[part 3 of 3: package /MICROSAR/Dcm_swc/ComponentTypes]
AUTOSAR XML (schema 00049)
package /MICROSAR/Dcm_swc/ComponentTypes
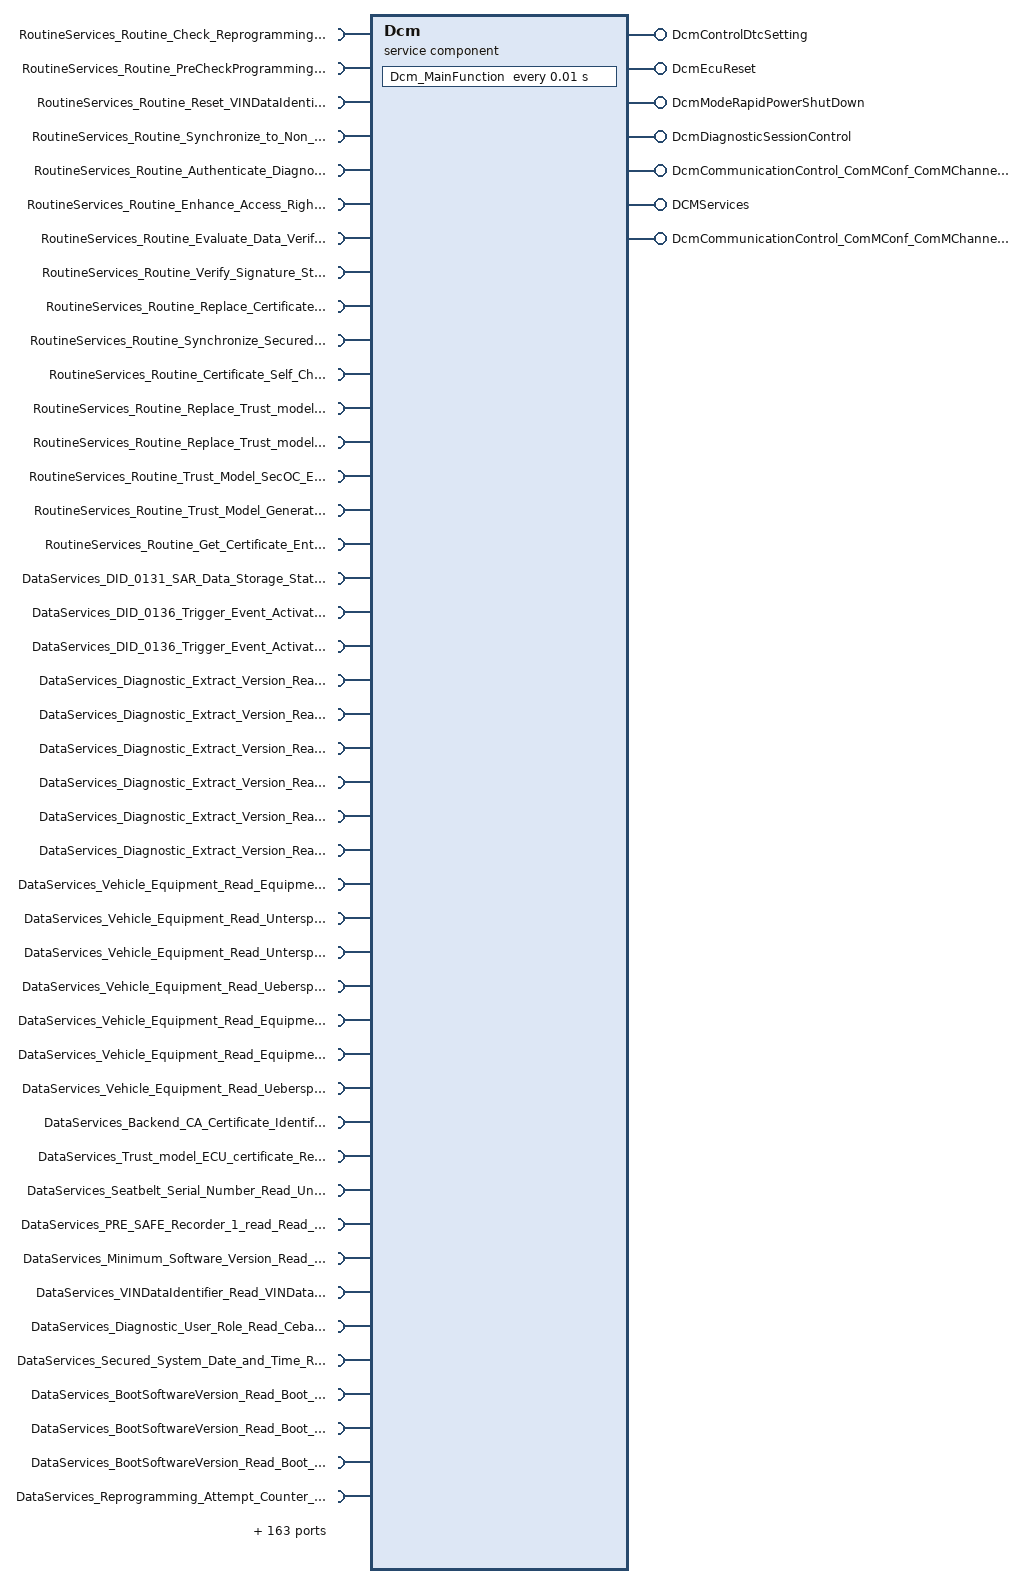
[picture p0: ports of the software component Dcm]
  service sw component type Dcm: category=SERVICE_COMPONENT
    6 x provide port:
      DcmControlDtcSetting: provided-interface=DcmControlDtcSetting
      DcmEcuReset: mode-switch-sender-com-spec{mode-group=DcmEcuReset, mode-switched-ack=timeout=0}, provided-interface=DcmEcuReset
      DcmModeRapidPowerShutDown: mode-switch-sender-com-spec{mode-group=DcmModeRapidPowerShutDown, mode-switched-ack=timeout=0}, provided-interface=DcmModeRapidPowerShutDown
      DcmDiagnosticSessionControl: provided-interface=DcmDiagnosticSessionControl
      DcmCommunicationControl_ComMConf_ComMChannel_RBTM_FL_BODY3_8uqv9blm85ehm0msat385m76v_03d5f5f6: provided-interface=DcmCommunicationControl_ComMConf_ComMChannel_RBTM_FL_BODY3_8uqv9blm85ehm0msat385m76v_03d5f5f6
      DCMServices: provided-interface=DCMServices
    138 x require port:
      RoutineServices_Routine_Check_Reprogramming_Preconditions_Start: required-interface=RoutineServices_Routine_Check_Reprogramming_Preconditions_Start
      RoutineServices_Routine_PreCheckProgrammingDependencies_Start: required-interface=RoutineServices_Routine_PreCheckProgrammingDependencies_Start
      RoutineServices_Routine_Reset_VINDataIdentifier_Start: required-interface=RoutineServices_Routine_Reset_VINDataIdentifier_Start
      RoutineServices_Routine_Synchronize_to_Non_volatile_Memory_Start: required-interface=RoutineServices_Routine_Synchronize_to_Non_volatile_Memory_Start
      RoutineServices_Routine_Authenticate_Diagnostic_User_or_Tester_Start: required-interface=RoutineServices_Routine_Authenticate_Diagnostic_User_or_Tester_Start
      RoutineServices_Routine_Enhance_Access_Rights_Start: required-interface=RoutineServices_Routine_Enhance_Access_Rights_Start
      RoutineServices_Routine_Evaluate_Data_Verification_Certificate_Start: required-interface=RoutineServices_Routine_Evaluate_Data_Verification_Certificate_Start
      RoutineServices_Routine_Verify_Signature_Start: required-interface=RoutineServices_Routine_Verify_Signature_Start
      RoutineServices_Routine_Replace_Certificates_Start: required-interface=RoutineServices_Routine_Replace_Certificates_Start
      RoutineServices_Routine_Synchronize_Secured_System_Date_and_Time_Start: required-interface=RoutineServices_Routine_Synchronize_Secured_System_Date_and_Time_Start
      RoutineServices_Routine_Certificate_Self_Check_Start: required-interface=RoutineServices_Routine_Certificate_Self_Check_Start
      RoutineServices_Routine_Replace_Trust_model_Certificates_Start: required-interface=RoutineServices_Routine_Replace_Trust_model_Certificates_Start
      RoutineServices_Routine_Replace_Trust_model_Root_Certificate_Start: required-interface=RoutineServices_Routine_Replace_Trust_model_Root_Certificate_Start
      RoutineServices_Routine_Trust_Model_SecOC_ECU_Shared_Secret_Distribution_Start: required-interface=RoutineServices_Routine_Trust_Model_SecOC_ECU_Shared_Secret_Distribution_Start
      RoutineServices_Routine_Trust_Model_Generate_Key_Pair_Start: required-interface=RoutineServices_Routine_Trust_Model_Generate_Key_Pair_Start
      RoutineServices_Routine_Get_Certificate_Entry_Start: required-interface=RoutineServices_Routine_Get_Certificate_Entry_Start
      DataServices_DID_0131_SAR_Data_Storage_Status: required-interface=DataServices_DID_0131_SAR_Data_Storage_Status
      DataServices_DID_0136_Trigger_Event_Activation_Status_Byte_2: required-interface=DataServices_DID_0136_Trigger_Event_Activation_Status_Byte_2
      DataServices_DID_0136_Trigger_Event_Activation_Status_Byte_1: required-interface=DataServices_DID_0136_Trigger_Event_Activation_Status_Byte_1
      DataServices_Diagnostic_Extract_Version_Read_Diagnostic_Extract_Minor_Version: required-interface=DataServices_Diagnostic_Extract_Version_Read_Diagnostic_Extract_Minor_Version
      DataServices_Diagnostic_Extract_Version_Read_CANdela_Version: required-interface=DataServices_Diagnostic_Extract_Version_Read_CANdela_Version
      DataServices_Diagnostic_Extract_Version_Read_Diagnostic_Extract_Major_Version: required-interface=DataServices_Diagnostic_Extract_Version_Read_Diagnostic_Extract_Major_Version
      DataServices_Diagnostic_Extract_Version_Read_DDM_Version: required-interface=DataServices_Diagnostic_Extract_Version_Read_DDM_Version
      DataServices_Diagnostic_Extract_Version_Read_Exported_Diagnostic_Variant: required-interface=DataServices_Diagnostic_Extract_Version_Read_Exported_Diagnostic_Variant
      DataServices_Diagnostic_Extract_Version_Read_Diagnostic_Extract_Patch_Version: required-interface=DataServices_Diagnostic_Extract_Version_Read_Diagnostic_Extract_Patch_Version
      DataServices_Vehicle_Equipment_Read_Equipment_1: required-interface=DataServices_Vehicle_Equipment_Read_Equipment_1
      DataServices_Vehicle_Equipment_Read_Unterspannungsbereichsschwelle: required-interface=DataServices_Vehicle_Equipment_Read_Unterspannungsbereichsschwelle
      DataServices_Vehicle_Equipment_Read_Unterspannungsabbruchschwelle: required-interface=DataServices_Vehicle_Equipment_Read_Unterspannungsabbruchschwelle
      DataServices_Vehicle_Equipment_Read_Ueberspannungsbereichsschwelle: required-interface=DataServices_Vehicle_Equipment_Read_Ueberspannungsbereichsschwelle
      DataServices_Vehicle_Equipment_Read_Equipment_3: required-interface=DataServices_Vehicle_Equipment_Read_Equipment_3
      DataServices_Vehicle_Equipment_Read_Equipment_2: required-interface=DataServices_Vehicle_Equipment_Read_Equipment_2
      DataServices_Vehicle_Equipment_Read_Ueberspannungsabbruchschwelle: required-interface=DataServices_Vehicle_Equipment_Read_Ueberspannungsabbruchschwelle
      DataServices_Backend_CA_Certificate_Identification_Read_Backend_CA_SubjectKeyIdentifier: required-interface=DataServices_Backend_CA_Certificate_Identification_Read_Backend_CA_SubjectKeyIdentifier
      DataServices_Trust_model_ECU_certificate_Read_Trust_model_ECU_Certificate: required-interface=DataServices_Trust_model_ECU_certificate_Read_Trust_model_ECU_Certificate
      DataServices_Seatbelt_Serial_Number_Read_Unique_Seatbelt_Serialnumber: required-interface=DataServices_Seatbelt_Serial_Number_Read_Unique_Seatbelt_Serialnumber
      DataServices_PRE_SAFE_Recorder_1_read_Read_CombinedDataElement: required-interface=DataServices_PRE_SAFE_Recorder_1_read_Read_CombinedDataElement
      DataServices_Minimum_Software_Version_Read_Minimum_Software_Version: required-interface=DataServices_Minimum_Software_Version_Read_Minimum_Software_Version
      DataServices_VINDataIdentifier_Read_VINDataIdentifier: required-interface=DataServices_VINDataIdentifier_Read_VINDataIdentifier
      DataServices_Diagnostic_User_Role_Read_Cebas_UserRole: required-interface=DataServices_Diagnostic_User_Role_Read_Cebas_UserRole
      DataServices_Secured_System_Date_and_Time_Read_GeneralizedTime: required-interface=DataServices_Secured_System_Date_and_Time_Read_GeneralizedTime
      DataServices_BootSoftwareVersion_Read_Boot_SW_year: required-interface=DataServices_BootSoftwareVersion_Read_Boot_SW_year
      DataServices_BootSoftwareVersion_Read_Boot_SW_patch_level: required-interface=DataServices_BootSoftwareVersion_Read_Boot_SW_patch_level
      DataServices_BootSoftwareVersion_Read_Boot_SW_week: required-interface=DataServices_BootSoftwareVersion_Read_Boot_SW_week
      DataServices_Reprogramming_Attempt_Counter_Read_Reprogramming_Attempts: required-interface=DataServices_Reprogramming_Attempt_Counter_Read_Reprogramming_Attempts
      DataServices_Standard_Application_SW_Package_Information_Read_Standard_Application_SW_Package_Major_Version: required-interface=DataServices_Standard_Application_SW_Package_Information_Read_Standard_Application_SW_Package_Major_Version
      DataServices_Standard_Application_SW_Package_Information_Read_Standard_Application_SW_Package_Patch_Level: required-interface=DataServices_Standard_Application_SW_Package_Information_Read_Standard_Application_SW_Package_Patch_Level
      DataServices_Standard_Application_SW_Package_Information_Read_Standard_Application_SW_Package_Minor_Version: required-interface=DataServices_Standard_Application_SW_Package_Information_Read_Standard_Application_SW_Package_Minor_Version
      DataServices_Standard_Application_SW_Package_Information_Read_Supplier_Identification: required-interface=DataServices_Standard_Application_SW_Package_Information_Read_Supplier_Identification
      DataServices_Standard_Application_SW_Package_Information_Read_Standard_Application_SW_Package_Build_Version: required-interface=DataServices_Standard_Application_SW_Package_Information_Read_Standard_Application_SW_Package_Build_Version
      DataServices_Dump_of_Vedoc_Relevant_Information_Read_PatchedObject: required-interface=DataServices_Dump_of_Vedoc_Relevant_Information_Read_PatchedObject
      DataServices_ECU_Name_Read_Diagnostic_ECU_Name: required-interface=DataServices_ECU_Name_Read_Diagnostic_ECU_Name
      DataServices_Security_Event_Log_Read_Security_Event_Log: required-interface=DataServices_Security_Event_Log_Read_Security_Event_Log
      DataServices_Adjust_ISO_15765_2_Block_Size_and_STmin_Parameter_Read_STmin_Value_as_defined_in_ISO_15765_2: required-interface=DataServices_Adjust_ISO_15765_2_Block_Size_and_STmin_Parameter_Read_STmin_Value_as_defined_in_ISO_15765_2
      DataServices_Adjust_ISO_15765_2_Block_Size_and_STmin_Parameter_Read_Block_Size_Value_as_defined_in_ISO_15765_2: required-interface=DataServices_Adjust_ISO_15765_2_Block_Size_and_STmin_Parameter_Read_Block_Size_Value_as_defined_in_ISO_15765_2
      DataServices_SSA_Version_Information_Read_SSA_Patch_Level: required-interface=DataServices_SSA_Version_Information_Read_SSA_Patch_Level
      DataServices_SSA_Version_Information_Read_SSA_Major_Version: required-interface=DataServices_SSA_Version_Information_Read_SSA_Major_Version
      DataServices_SSA_Version_Information_Read_SSA_Minor_Version: required-interface=DataServices_SSA_Version_Information_Read_SSA_Minor_Version
      DataServices_SoftwareSupplier_Read_Software_Logical_Block_Supplier_Identification: required-interface=DataServices_SoftwareSupplier_Read_Software_Logical_Block_Supplier_Identification
      DataServices_DDS_Package_Release_Read_DDS_Package_Release_of_Boot_Software_Month_Boot: required-interface=DataServices_DDS_Package_Release_Read_DDS_Package_Release_of_Boot_Software_Month_Boot
      DataServices_DDS_Package_Release_Read_DDS_Package_Release_of_Application_Software_Year_Appl: required-interface=DataServices_DDS_Package_Release_Read_DDS_Package_Release_of_Application_Software_Year_Appl
      DataServices_DDS_Package_Release_Read_DDS_Package_Release_of_Application_Software_Month_Appl: required-interface=DataServices_DDS_Package_Release_Read_DDS_Package_Release_of_Application_Software_Month_Appl
      DataServices_DDS_Package_Release_Read_DDS_Package_Release_of_Boot_Software_Year_Boot: required-interface=DataServices_DDS_Package_Release_Read_DDS_Package_Release_of_Boot_Software_Year_Boot
      DataServices_Security_Event_Log_Current_Counter_Values_Read_Security_Event_Log_Current_Counter_Values: required-interface=DataServices_Security_Event_Log_Current_Counter_Values_Read_Security_Event_Log_Current_Counter_Values
      DataServices_Supported_configuration_mechanisms_Read_Config_mechanisms: required-interface=DataServices_Supported_configuration_mechanisms_Read_Config_mechanisms
      DataServices_CAN_input_Read_Neues_Bitfeld_6: required-interface=DataServices_CAN_input_Read_Neues_Bitfeld_6
      DataServices_CAN_input_Read_Neues_Bitfeld_5: required-interface=DataServices_CAN_input_Read_Neues_Bitfeld_5
      DataServices_CAN_input_Read_Neues_Bitfeld_4: required-interface=DataServices_CAN_input_Read_Neues_Bitfeld_4
      DataServices_CAN_input_Read_Neues_Bitfeld_3: required-interface=DataServices_CAN_input_Read_Neues_Bitfeld_3
      DataServices_CAN_input_Read_Supply_battery_voltage: required-interface=DataServices_CAN_input_Read_Supply_battery_voltage
      DataServices_CAN_input_Read_Neues_Bitfeld_2: required-interface=DataServices_CAN_input_Read_Neues_Bitfeld_2
      DataServices_CAN_input_Read_Neues_Bitfeld_1: required-interface=DataServices_CAN_input_Read_Neues_Bitfeld_1
      DataServices_SecOC_Vehicle_Shared_Secret_Hash_Read_SecOC_Vehicle_Shared_Secret_Hash: required-interface=DataServices_SecOC_Vehicle_Shared_Secret_Hash_Read_SecOC_Vehicle_Shared_Secret_Hash
      DataServices_Trust_model_ECU_CSR_Read_Trust_model_ECU_CSR: required-interface=DataServices_Trust_model_ECU_CSR_Read_Trust_model_ECU_CSR
      DataServices_Root_CA_Certificate_Read_Root_CA_Certificate: required-interface=DataServices_Root_CA_Certificate_Read_Root_CA_Certificate
      DataServices_ECUSerialNumberDataIdentifier_Read_ECU_Serial_Number: required-interface=DataServices_ECUSerialNumberDataIdentifier_Read_ECU_Serial_Number
      DataServices_VIN_Status_Read_VIN_Lock_Status: required-interface=DataServices_VIN_Status_Read_VIN_Lock_Status
      DataServices_VIN_Status_Read_VIN_Status: required-interface=DataServices_VIN_Status_Read_VIN_Status
      DataServices_Status_SSA_Pre_Compile_Switches_Read_Precompile_switch: required-interface=DataServices_Status_SSA_Pre_Compile_Switches_Read_Precompile_switch
      DataServices_PRE_SAFE_Recorder_2_read_Read_CombinedDataElement: required-interface=DataServices_PRE_SAFE_Recorder_2_read_Read_CombinedDataElement
      DataServices_BSR_Counter_read_Read_BSR_Counter: required-interface=DataServices_BSR_Counter_read_Read_BSR_Counter
      DataServices_Vehicle_Odometer_in_Low_Resolution_Read_Vehicle_Odometer_in_Low_Resolution: required-interface=DataServices_Vehicle_Odometer_in_Low_Resolution_Read_Vehicle_Odometer_in_Low_Resolution
      DataServices_HardwareSupplier_Read_Hardware_Supplier_Identification: required-interface=DataServices_HardwareSupplier_Read_Hardware_Supplier_Identification
      DataServices_MercedesCarGroupSoftware_Read_Software_Logical_Block_Numbers: required-interface=DataServices_MercedesCarGroupSoftware_Read_Software_Logical_Block_Numbers
      DataServices_SecOC_PDU_Data_IDs_and_Key_CMACs_Read_Secured_PDU_Data_IDs_and_Key_CMACs: required-interface=DataServices_SecOC_PDU_Data_IDs_and_Key_CMACs_Read_Secured_PDU_Data_IDs_and_Key_CMACs
      DataServices_Current_Operating_Time_Read_Current_Operating_Time: required-interface=DataServices_Current_Operating_Time_Read_Current_Operating_Time
      DataServices_Current_Operating_Time_Read_Operating_Time_Status: required-interface=DataServices_Current_Operating_Time_Read_Operating_Time_Status
      DataServices_Trust_model_Root_CA_certificate_Read_Trust_model_Root_CA_certificate: required-interface=DataServices_Trust_model_Root_CA_certificate_Read_Trust_model_Root_CA_certificate
      DataServices_RandomNumber_Read_Generated_Random_Number_Result: required-interface=DataServices_RandomNumber_Read_Generated_Random_Number_Result
      DataServices_RandomNumber_Read_Generated_Random_Number: required-interface=DataServices_RandomNumber_Read_Generated_Random_Number
      DataServices_MercedesCarGroupHardware_Read_Hardware_Part_Number: required-interface=DataServices_MercedesCarGroupHardware_Read_Hardware_Part_Number
      DataServices_Internal_ECU_information_Read_ECU_Temperature: required-interface=DataServices_Internal_ECU_information_Read_ECU_Temperature
      DataServices_Internal_ECU_information_Read_MOTOR_Current: required-interface=DataServices_Internal_ECU_information_Read_MOTOR_Current
      DataServices_Internal_ECU_information_Read_Autosar_System_State_EcuM_State: required-interface=DataServices_Internal_ECU_information_Read_Autosar_System_State_EcuM_State
      DataServices_Backend_CA_Certificate_Read_Backend_CA_Certificate: required-interface=DataServices_Backend_CA_Certificate_Read_Backend_CA_Certificate
      DataServices_Trust_model_Intermediate_CA_certificate_Read_Trust_model_Intermediate_CA_Certificate: required-interface=DataServices_Trust_model_Intermediate_CA_certificate_Read_Trust_model_Intermediate_CA_Certificate
      DataServices_Diagnostic_Authentication_Certificate_Identification_Read_Diagnostic_Authentication_Certificate_Serial_Number: required-interface=DataServices_Diagnostic_Authentication_Certificate_Identification_Read_Diagnostic_Authentication_Certificate_Serial_Number
      DataServices_Diagnostic_Authentication_Certificate_Identification_Read_Diagnostic_Authentication_Certificate_Issuer: required-interface=DataServices_Diagnostic_Authentication_Certificate_Identification_Read_Diagnostic_Authentication_Certificate_Issuer
      DataServices_SecOC_PDU_Data_IDs_and_Key_Checksum_Read_Secured_PDU_Data_IDs_and_Key_Checksum: required-interface=DataServices_SecOC_PDU_Data_IDs_and_Key_Checksum_Read_Secured_PDU_Data_IDs_and_Key_Checksum
      DataServices_System_Time_read_Read_System_time: required-interface=DataServices_System_Time_read_Read_System_time
      DataServices_Trust_Model_Request_ephemeral_public_key_Read_Data_Signature: required-interface=DataServices_Trust_Model_Request_ephemeral_public_key_Read_Data_Signature
      DataServices_Trust_Model_Request_ephemeral_public_key_Read_Ephemeral_ECU_Public_Key: required-interface=DataServices_Trust_Model_Request_ephemeral_public_key_Read_Ephemeral_ECU_Public_Key
      DataServices_Trust_Model_Request_ephemeral_public_key_Read_Certificates: required-interface=DataServices_Trust_Model_Request_ephemeral_public_key_Read_Certificates
      DataServices_Trust_Model_Request_ephemeral_public_key_Read_Nonce: required-interface=DataServices_Trust_Model_Request_ephemeral_public_key_Read_Nonce
      DataServices_HW_input_Read_Voltage_KL30t: required-interface=DataServices_HW_input_Read_Voltage_KL30t
      DataServices_HW_input_Read_Voltage_Motor: required-interface=DataServices_HW_input_Read_Voltage_Motor
      DataServices_Diagnostic_Trace_Memory_Read_Diagnostic_Trace_Memory: required-interface=DataServices_Diagnostic_Trace_Memory_Read_Diagnostic_Trace_Memory
      DataServices_ReadFingerprint_Read_Software_Fingerprint_s: required-interface=DataServices_ReadFingerprint_Read_Software_Fingerprint_s
      DataServices_Trust_model_full_chain_of_trust_certificates_Read_Trust_model_certificates: required-interface=DataServices_Trust_model_full_chain_of_trust_certificates_Read_Trust_model_certificates
      DataServices_ZZZ_Vehicle_Equipment_Development_Read_Zykluszeit_Messtechnik: required-interface=DataServices_ZZZ_Vehicle_Equipment_Development_Read_Zykluszeit_Messtechnik
      DataServices_ZZZ_Vehicle_Equipment_Development_Read_Bitfield: required-interface=DataServices_ZZZ_Vehicle_Equipment_Development_Read_Bitfield
      DataServices_PRE_SAFE_Counter_read_Read_CombinedDataElement: required-interface=DataServices_PRE_SAFE_Counter_read_Read_CombinedDataElement
      DataServices_Trust_model_Backend_CA_certificate_Read_Trust_model_Backend_CA_certificate: required-interface=DataServices_Trust_model_Backend_CA_certificate_Read_Trust_model_Backend_CA_certificate
      DataServices_ActiveDiagnosticInformation_Read_Session: required-interface=DataServices_ActiveDiagnosticInformation_Read_Session
      DataServices_ActiveDiagnosticInformation_Read_Identification: required-interface=DataServices_ActiveDiagnosticInformation_Read_Identification
      DataServices_Real_Time_Offset_Read_TickCount: required-interface=DataServices_Real_Time_Offset_Read_TickCount
      DataServices_Real_Time_Offset_Read_Real_Time_Offset: required-interface=DataServices_Real_Time_Offset_Read_Real_Time_Offset
      DataServices_SoftwareVersion_Read_Software_Logical_Block_Version_Information: required-interface=DataServices_SoftwareVersion_Read_Software_Logical_Block_Version_Information
      DataServices_CAN_output_Read_CANoutput1: required-interface=DataServices_CAN_output_Read_CANoutput1
      DataServices_Access_Control_List_Version_Read_Basic_ACL_Version_Generation_Time_GTC: required-interface=DataServices_Access_Control_List_Version_Read_Basic_ACL_Version_Generation_Time_GTC
      DataServices_Access_Control_List_Version_Read_ECU_indvidual_ACL_Version_Generation_Time_GTC: required-interface=DataServices_Access_Control_List_Version_Read_ECU_indvidual_ACL_Version_Generation_Time_GTC
      DataServices_Access_Control_List_Version_Read_Basic_ACL_Hash: required-interface=DataServices_Access_Control_List_Version_Read_Basic_ACL_Hash
      DataServices_Access_Control_List_Version_Read_Basic_ACL_Version_Candela_File_Version_Patch: required-interface=DataServices_Access_Control_List_Version_Read_Basic_ACL_Version_Candela_File_Version_Patch
      DataServices_Access_Control_List_Version_Read_ECU_indvidual_ACL_Version_Candela_File_Version_Patch: required-interface=DataServices_Access_Control_List_Version_Read_ECU_indvidual_ACL_Version_Candela_File_Version_Patch
      DataServices_Access_Control_List_Version_Read_ECU_indvidual_ACL_Hash: required-interface=DataServices_Access_Control_List_Version_Read_ECU_indvidual_ACL_Hash
      DataServices_Access_Control_List_Version_Read_ECU_indvidual_ACL_Version_Candela_File_Version_Minor: required-interface=DataServices_Access_Control_List_Version_Read_ECU_indvidual_ACL_Version_Candela_File_Version_Minor
      DataServices_Access_Control_List_Version_Read_ECU_indvidual_ACL_Version_Candela_File_Version_Major: required-interface=DataServices_Access_Control_List_Version_Read_ECU_indvidual_ACL_Version_Candela_File_Version_Major
      DataServices_Access_Control_List_Version_Read_Basic_ACL_Version_Candela_File_Version_Minor: required-interface=DataServices_Access_Control_List_Version_Read_Basic_ACL_Version_Candela_File_Version_Minor
      DataServices_Access_Control_List_Version_Read_Basic_ACL_Version_Candela_File_Version_Major: required-interface=DataServices_Access_Control_List_Version_Read_Basic_ACL_Version_Candela_File_Version_Major
      DataServices_SecOC_Local_TickCount_Read_TickCount: required-interface=DataServices_SecOC_Local_TickCount_Read_TickCount
      DataServices_HardwareVersion_Read_HW_year: required-interface=DataServices_HardwareVersion_Read_HW_year
      DataServices_HardwareVersion_Read_HW_week: required-interface=DataServices_HardwareVersion_Read_HW_week
      DataServices_HardwareVersion_Read_HW_patch_level: required-interface=DataServices_HardwareVersion_Read_HW_patch_level
      ServiceRequestManufacturerNotification_DcmDslServiceRequestManufacturerNotification_RightsM: required-interface=ServiceRequestNotification
      ServiceRequestManufacturerNotification_DcmDslServiceRequestManufacturerNotification_Coding: required-interface=ServiceRequestNotification
      ServiceRequestManufacturerNotification_DcmDslServiceRequestManufacturerNotification_ResetPreconditionCheck: required-interface=ServiceRequestNotification
      DataServices_ECU_Location_Read_Side_Allocation: required-interface=DataServices_ECU_Location_Read_Side_Allocation
      DataServices_Cycle_configuration_Read_Cycles: required-interface=DataServices_Cycle_configuration_Read_Cycles
      DataServices_Steps_library_Read_Steps: required-interface=DataServices_Steps_library_Read_Steps
    provide port DcmCommunicationControl_ComMConf_ComMChannel_RBTM_FR_BODY3_4xwwtd59665s787n6ctawh7k8_23a94727: provided-interface=DcmCommunicationControl_ComMConf_ComMChannel_RBTM_FR_BODY3_4xwwtd59665s787n6ctawh7k8_23a94727
    69 x require port:
      RoutineServices_Routine_Status_of_Post_Production_Flag_Start: required-interface=RoutineServices_Routine_Status_of_Post_Production_Flag_Start
      RoutineServices_Routine_Trigger_Presafe_Display_Request_Start: required-interface=RoutineServices_Routine_Trigger_Presafe_Display_Request_Start
      RoutineServices_Routine_Trigger_BSR_Start: required-interface=RoutineServices_Routine_Trigger_BSR_Start
      RoutineServices_Routine_Trigger_Tensioning_Cycle_Start: required-interface=RoutineServices_Routine_Trigger_Tensioning_Cycle_Start
      DataServices_Obsolescence_Data_Read_Obsolescence_Data_haptic_Warning_Threshold_Yellow_to_Red: required-interface=DataServices_Obsolescence_Data_Read_Obsolescence_Data_haptic_Warning_Threshold_Yellow_to_Red
      DataServices_Obsolescence_Data_Read_Obsolescence_Data_PRE_SAFE_Lvl_4_5_Threshold_Green_to_Yellow: required-interface=DataServices_Obsolescence_Data_Read_Obsolescence_Data_PRE_SAFE_Lvl_4_5_Threshold_Green_to_Yellow
      DataServices_Obsolescence_Data_Read_Obsolescence_Data_BSR_Threshold_Yellow_to_Red: required-interface=DataServices_Obsolescence_Data_Read_Obsolescence_Data_BSR_Threshold_Yellow_to_Red
      DataServices_Obsolescence_Data_Read_Obsolescence_Data_haptic_Warning_Threshold_Green_to_Yellow: required-interface=DataServices_Obsolescence_Data_Read_Obsolescence_Data_haptic_Warning_Threshold_Green_to_Yellow
      DataServices_Obsolescence_Data_Read_Obsolescence_Data_BSR_Current_Value: required-interface=DataServices_Obsolescence_Data_Read_Obsolescence_Data_BSR_Current_Value
      DataServices_Obsolescence_Data_Read_Obsolescence_Data_PRE_CRASH_Threshold_Yellow_to_Red: required-interface=DataServices_Obsolescence_Data_Read_Obsolescence_Data_PRE_CRASH_Threshold_Yellow_to_Red
      DataServices_Obsolescence_Data_Read_Obsolescence_Data_PRE_SAFE_Lvl_4_5_Threshold_Yellow_to_Red: required-interface=DataServices_Obsolescence_Data_Read_Obsolescence_Data_PRE_SAFE_Lvl_4_5_Threshold_Yellow_to_Red
      DataServices_Obsolescence_Data_Read_Obsolescence_Data_PRE_CRASH_Threshold_Green_to_Yellow: required-interface=DataServices_Obsolescence_Data_Read_Obsolescence_Data_PRE_CRASH_Threshold_Green_to_Yellow
      DataServices_Obsolescence_Data_Read_Obsolescence_Data_PRE_SAFE_Lvl_4_5_Current_Value: required-interface=DataServices_Obsolescence_Data_Read_Obsolescence_Data_PRE_SAFE_Lvl_4_5_Current_Value
      DataServices_Obsolescence_Data_Read_Obsolescence_Data_haptic_Warning_Current_Value: required-interface=DataServices_Obsolescence_Data_Read_Obsolescence_Data_haptic_Warning_Current_Value
      DataServices_Obsolescence_Data_Read_Obsolescence_Data_BSR_Threshold_Green_to_Yellow: required-interface=DataServices_Obsolescence_Data_Read_Obsolescence_Data_BSR_Threshold_Green_to_Yellow
      DataServices_Obsolescence_Data_Read_Obsolescence_Data_PRE_CRASH_Current_Value: required-interface=DataServices_Obsolescence_Data_Read_Obsolescence_Data_PRE_CRASH_Current_Value
      DataServices_Availability_Data_Read_Availability_Data_PRE_SAFE_haptic_warning: required-interface=DataServices_Availability_Data_Read_Availability_Data_PRE_SAFE_haptic_warning
      DataServices_Standard_Application_SW_Package_Information_Read_AUTOSAR_Platform: required-interface=DataServices_Standard_Application_SW_Package_Information_Read_AUTOSAR_Platform
      DataServices_CAN_output_Read_PS_Curve_XX_Stat_ST3: required-interface=DataServices_CAN_output_Read_PS_Curve_XX_Stat_ST3
      DataServices_CAN_output_Read_RBTMxx_Actv_Lvl_ST35: required-interface=DataServices_CAN_output_Read_RBTMxx_Actv_Lvl_ST35
      DataServices_CAN_output_Read_RBTMxx_SP_ActvClient_ST35: required-interface=DataServices_CAN_output_Read_RBTMxx_SP_ActvClient_ST35
      DataServices_CAN_output_Read_RBTMxx_SP_FctPrecond_Stat_ST35: required-interface=DataServices_CAN_output_Read_RBTMxx_SP_FctPrecond_Stat_ST35
      DataServices_Trust_Model_Root_Replacement_Key_Read_Root_Replacement_Key: required-interface=DataServices_Trust_Model_Root_Replacement_Key_Read_Root_Replacement_Key
      DataServices_Last_Warm_Reset_Parameters_Read_Reset_Cause_Counter: required-interface=DataServices_Last_Warm_Reset_Parameters_Read_Reset_Cause_Counter
      DataServices_Last_Warm_Reset_Parameters_Read_Last_Detected_Warm_Reset_Cause: required-interface=DataServices_Last_Warm_Reset_Parameters_Read_Last_Detected_Warm_Reset_Cause
      RoutineServices_Routine_Cycle_Execution_Start: required-interface=RoutineServices_Routine_Cycle_Execution_Start
      DataServices_Measurement_Frames_Configuration_Read_CombinedSignal: required-interface=DataServices_Measurement_Frames_Configuration_Read_CombinedSignal
      DataServices_Measurement_Frame_Block_12_Config_Read_CombinedSignal: required-interface=DataServices_Measurement_Frame_Block_12_Config_Read_CombinedSignal
      DataServices_HB_Calibration_Read_CombinedSignal: required-interface=DataServices_HB_Calibration_Read_CombinedSignal
      DataServices_AEC_Status_Read_AEC_Status: required-interface=DataServices_AEC_Status_Read_AEC_Status
      DataServices_Reset_Cause_Management_Read_Reset_Cause: required-interface=DataServices_Reset_Cause_Management_Read_Reset_Cause
      RoutineServices_Routine_Clear_Resource_Consumption_Data_Start: required-interface=RoutineServices_Routine_Clear_Resource_Consumption_Data_Start
      DataServices_Task_Response_Time_Read_Task_histograms: required-interface=DataServices_Task_Response_Time_Read_Task_histograms
      DataServices_Stack_Load_Read_Maximum: required-interface=DataServices_Stack_Load_Read_Maximum
      DataServices_CPU_Load_Read_CPU_load_histograms: required-interface=DataServices_CPU_Load_Read_CPU_load_histograms
      DataServices_Vehicle_Equipment_Read_Equipment_6: required-interface=DataServices_Vehicle_Equipment_Read_Equipment_6
      DataServices_Vehicle_Equipment_Read_Equipment_5: required-interface=DataServices_Vehicle_Equipment_Read_Equipment_5
      DataServices_Vehicle_Equipment_Read_Equipment_4: required-interface=DataServices_Vehicle_Equipment_Read_Equipment_4
      DataServices_Tensioning_Cycle_BSR_Read_CombinedSignal: required-interface=DataServices_Tensioning_Cycle_BSR_Read_CombinedSignal
      DataServices_Release_Cycles_BSR_and_PreSafe_Read_CombinedSignal: required-interface=DataServices_Release_Cycles_BSR_and_PreSafe_Read_CombinedSignal
      DataServices_PreSafe_Cycles_Level_1_8_Read_CombinedSignal: required-interface=DataServices_PreSafe_Cycles_Level_1_8_Read_CombinedSignal
      DataServices_Global_Time_Sync_Measured_Values_Read_GTSM: required-interface=DataServices_Global_Time_Sync_Measured_Values_Read_GTSM
      DataServices_Memory_Usage_Cycles_Read_Memory_Usage_Cycles: required-interface=DataServices_Memory_Usage_Cycles_Read_Memory_Usage_Cycles
      DataServices_CAN_input_Read_Neues_Bitfeld_8: required-interface=DataServices_CAN_input_Read_Neues_Bitfeld_8
      DataServices_CAN_input_Read_Neues_Bitfeld_7: required-interface=DataServices_CAN_input_Read_Neues_Bitfeld_7
      DataServices_HSM_Identification_Read_HSM_MB_Version_HW_patch_level: required-interface=DataServices_HSM_Identification_Read_HSM_MB_Version_HW_patch_level
      DataServices_HSM_Identification_Read_HSM_MB_Supplier_Version_HW_week: required-interface=DataServices_HSM_Identification_Read_HSM_MB_Supplier_Version_HW_week
      DataServices_HSM_Identification_Read_HSM_MB_Supplier_Version_HW_patch_level: required-interface=DataServices_HSM_Identification_Read_HSM_MB_Supplier_Version_HW_patch_level
      DataServices_HSM_Identification_Read_HSM_MB_Version_HW_year: required-interface=DataServices_HSM_Identification_Read_HSM_MB_Version_HW_year
      DataServices_HSM_Identification_Read_HSM_MB_Partnumber: required-interface=DataServices_HSM_Identification_Read_HSM_MB_Partnumber
      DataServices_HSM_Identification_Read_HSM_MB_Supplier_Version_HW_year: required-interface=DataServices_HSM_Identification_Read_HSM_MB_Supplier_Version_HW_year
      DataServices_HSM_Identification_Read_HSM_MB_Version_HW_week: required-interface=DataServices_HSM_Identification_Read_HSM_MB_Version_HW_week
      DataServices_SW_Version_Read_SW_Version: required-interface=DataServices_SW_Version_Read_SW_Version
      DataServices_Hardware_Version_Information_Write_HW_year: required-interface=DataServices_Hardware_Version_Information_Write_HW_year
      DataServices_Hardware_Version_Information_Write_HW_week: required-interface=DataServices_Hardware_Version_Information_Write_HW_week
      DataServices_Hardware_Version_Information_Write_HW_patch_level: required-interface=DataServices_Hardware_Version_Information_Write_HW_patch_level
      DataServices_Standard_Application_SW_Package_Information_Read_C_P_Identification: required-interface=DataServices_Standard_Application_SW_Package_Information_Read_C_P_Identification
      DataServices_Calibration_Identifications_CAL_ID_Read_Calibration_Identification: required-interface=DataServices_Calibration_Identifications_CAL_ID_Read_Calibration_Identification
      DataServices_Calibration_Identifications_CAL_ID_Write_Calibration_Identification: required-interface=DataServices_Calibration_Identifications_CAL_ID_Write_Calibration_Identification
      DataServices_Calibration_Identifications_CAL_ID_Write_Number_of_data_items: required-interface=DataServices_Calibration_Identifications_CAL_ID_Write_Number_of_data_items
      DataServices_ECU_serial_number_Read_PCBA_Programmed_Part_number: required-interface=DataServices_ECU_serial_number_Read_PCBA_Programmed_Part_number
      DataServices_ECU_serial_number_Read_ECU_traceability_number: required-interface=DataServices_ECU_serial_number_Read_ECU_traceability_number
      RoutineServices_Routine_Erase_All_Start: required-interface=RoutineServices_Routine_Erase_All_Start
      RoutineServices_Routine_Force_External_WDG_Start: required-interface=RoutineServices_Routine_Force_External_WDG_Start
      DataServices_Customer_Settings_Read_BltSlckDec_Md_Stat: required-interface=DataServices_Customer_Settings_Read_BltSlckDec_Md_Stat
      DataServices_Customer_Settings_Read_PS_Curve_Stat: required-interface=DataServices_Customer_Settings_Read_PS_Curve_Stat
      DataServices_Trust_Model_CSR_Supplier_Signature_Read_Trust_Model_CSR_Supplier_Signature: required-interface=DataServices_Trust_Model_CSR_Supplier_Signature_Read_Trust_Model_CSR_Supplier_Signature
      DataServices_Velocity_PI_Regulation_Coefficient_Read_Input_Velocity_Coefficient: required-interface=DataServices_Velocity_PI_Regulation_Coefficient_Read_Input_Velocity_Coefficient
      DataServices_Temperature_Sensor_Calibration_Point_Read_Offset_Point: required-interface=DataServices_Temperature_Sensor_Calibration_Point_Read_Offset_Point
    behavior DcmInternalBehavior: data-type-mapping=DcmMappingSet, handle-termination-and-restart=NO-SUPPORT, included-data-type-set=data-type=[Dcm_ConfirmationStatusType, Dcm_OpStatusType, Dcm_NegativeResponseCodeType, Dcm_ProtocolType, Dcm_RequestKindType, Dcm_SesCtrlType, Dcm_ControlDtcSettingType, Dcm_EcuResetType, Dcm_ModeRapidPowerShutDownType, Dcm_DiagnosticSessionControlType, Dcm_CommunicationModeType]
      timing event Timer_Dcm_MainFunction: start-on-event=Dcm_MainFunction, period=0.01
      5 x operation invoked event:
        OpEventGetActiveProtocol_GetActiveProtocol_DCMServices: start-on-event=GetActiveProtocol, operation=DCMServices.GetActiveProtocol
        OpEventGetSesCtrlType_GetSesCtrlType_DCMServices: start-on-event=GetSesCtrlType, operation=DCMServices.GetSesCtrlType
        OpEventResetToDefaultSession_ResetToDefaultSession_DCMServices: start-on-event=ResetToDefaultSession, operation=DCMServices.ResetToDefaultSession
        OpEventSetActiveDiagnostic_SetActiveDiagnostic_DCMServices: start-on-event=SetActiveDiagnostic, operation=DCMServices.SetActiveDiagnostic
        OpEventGetRequestKind_GetRequestKind_DCMServices: start-on-event=GetRequestKind, operation=DCMServices.GetRequestKind
      port-api-options:
        enable-take-address=true, indirect-api=false, port=DcmControlDtcSetting
        enable-take-address=true, indirect-api=false, port=DcmEcuReset
        enable-take-address=true, indirect-api=false, port=DcmModeRapidPowerShutDown
        enable-take-address=true, indirect-api=false, port=DcmDiagnosticSessionControl
        enable-take-address=true, indirect-api=false, port=DcmCommunicationControl_ComMConf_ComMChannel_RBTM_FL_BODY3_8uqv9blm85ehm0msat385m76v_03d5f5f6
        enable-take-address=true, indirect-api=false, port=DcmCommunicationControl_ComMConf_ComMChannel_RBTM_FR_BODY3_4xwwtd59665s787n6ctawh7k8_23a94727
        enable-take-address=true, indirect-api=false, port=DCMServices
        enable-take-address=true, indirect-api=false, port=ServiceRequestManufacturerNotification_DcmDslServiceRequestManufacturerNotification_ResetPreconditionCheck
        enable-take-address=true, indirect-api=false, port=ServiceRequestManufacturerNotification_DcmDslServiceRequestManufacturerNotification_RightsM
        enable-take-address=true, indirect-api=false, port=ServiceRequestManufacturerNotification_DcmDslServiceRequestManufacturerNotification_Coding
        enable-take-address=true, indirect-api=false, port=RoutineServices_Routine_Check_Reprogramming_Preconditions_Start
        enable-take-address=true, indirect-api=false, port=RoutineServices_Routine_PreCheckProgrammingDependencies_Start
        enable-take-address=true, indirect-api=false, port=RoutineServices_Routine_Clear_Resource_Consumption_Data_Start
        enable-take-address=true, indirect-api=false, port=RoutineServices_Routine_Reset_VINDataIdentifier_Start
        enable-take-address=true, indirect-api=false, port=RoutineServices_Routine_Synchronize_to_Non_volatile_Memory_Start
        enable-take-address=true, indirect-api=false, port=RoutineServices_Routine_Authenticate_Diagnostic_User_or_Tester_Start
        enable-take-address=true, indirect-api=false, port=RoutineServices_Routine_Enhance_Access_Rights_Start
        enable-take-address=true, indirect-api=false, port=RoutineServices_Routine_Evaluate_Data_Verification_Certificate_Start
        enable-take-address=true, indirect-api=false, port=RoutineServices_Routine_Verify_Signature_Start
        enable-take-address=true, indirect-api=false, port=RoutineServices_Routine_Replace_Certificates_Start
        enable-take-address=true, indirect-api=false, port=RoutineServices_Routine_Synchronize_Secured_System_Date_and_Time_Start
        enable-take-address=true, indirect-api=false, port=RoutineServices_Routine_Certificate_Self_Check_Start
        enable-take-address=true, indirect-api=false, port=RoutineServices_Routine_Status_of_Post_Production_Flag_Start
        enable-take-address=true, indirect-api=false, port=RoutineServices_Routine_Replace_Trust_model_Certificates_Start
        enable-take-address=true, indirect-api=false, port=RoutineServices_Routine_Replace_Trust_model_Root_Certificate_Start
        enable-take-address=true, indirect-api=false, port=RoutineServices_Routine_Trust_Model_SecOC_ECU_Shared_Secret_Distribution_Start
        enable-take-address=true, indirect-api=false, port=RoutineServices_Routine_Trust_Model_Generate_Key_Pair_Start
        enable-take-address=true, indirect-api=false, port=RoutineServices_Routine_Get_Certificate_Entry_Start
        enable-take-address=true, indirect-api=false, port=RoutineServices_Routine_Trigger_Presafe_Display_Request_Start
        enable-take-address=true, indirect-api=false, port=RoutineServices_Routine_Trigger_BSR_Start
        enable-take-address=true, indirect-api=false, port=RoutineServices_Routine_Trigger_Tensioning_Cycle_Start
        enable-take-address=true, indirect-api=false, port=RoutineServices_Routine_Cycle_Execution_Start
        enable-take-address=true, indirect-api=false, port=DataServices_DID_0131_SAR_Data_Storage_Status
        enable-take-address=true, indirect-api=false, port=DataServices_DID_0136_Trigger_Event_Activation_Status_Byte_2
        enable-take-address=true, indirect-api=false, port=DataServices_DID_0136_Trigger_Event_Activation_Status_Byte_1
        enable-take-address=true, indirect-api=false, port=DataServices_Diagnostic_Extract_Version_Read_Diagnostic_Extract_Minor_Version
        enable-take-address=true, indirect-api=false, port=DataServices_Diagnostic_Extract_Version_Read_CANdela_Version
        enable-take-address=true, indirect-api=false, port=DataServices_Diagnostic_Extract_Version_Read_Diagnostic_Extract_Major_Version
        enable-take-address=true, indirect-api=false, port=DataServices_Diagnostic_Extract_Version_Read_DDM_Version
        enable-take-address=true, indirect-api=false, port=DataServices_Diagnostic_Extract_Version_Read_Exported_Diagnostic_Variant
        enable-take-address=true, indirect-api=false, port=DataServices_Diagnostic_Extract_Version_Read_Diagnostic_Extract_Patch_Version
        enable-take-address=true, indirect-api=false, port=DataServices_Vehicle_Equipment_Read_Equipment_1
        enable-take-address=true, indirect-api=false, port=DataServices_Vehicle_Equipment_Read_Unterspannungsbereichsschwelle
        enable-take-address=true, indirect-api=false, port=DataServices_Vehicle_Equipment_Read_Unterspannungsabbruchschwelle
        enable-take-address=true, indirect-api=false, port=DataServices_Vehicle_Equipment_Read_Ueberspannungsbereichsschwelle
        enable-take-address=true, indirect-api=false, port=DataServices_Vehicle_Equipment_Read_Equipment_3
        enable-take-address=true, indirect-api=false, port=DataServices_Vehicle_Equipment_Read_Equipment_2
        enable-take-address=true, indirect-api=false, port=DataServices_Vehicle_Equipment_Read_Ueberspannungsabbruchschwelle
        enable-take-address=true, indirect-api=false, port=DataServices_Vehicle_Equipment_Read_Equipment_6
        enable-take-address=true, indirect-api=false, port=DataServices_Vehicle_Equipment_Read_Equipment_5
        enable-take-address=true, indirect-api=false, port=DataServices_Vehicle_Equipment_Read_Equipment_4
        enable-take-address=true, indirect-api=false, port=DataServices_Backend_CA_Certificate_Identification_Read_Backend_CA_SubjectKeyIdentifier
        enable-take-address=true, indirect-api=false, port=DataServices_Trust_model_ECU_certificate_Read_Trust_model_ECU_Certificate
        enable-take-address=true, indirect-api=false, port=DataServices_Seatbelt_Serial_Number_Read_Unique_Seatbelt_Serialnumber
        enable-take-address=true, indirect-api=false, port=DataServices_Obsolescence_Data_Read_Obsolescence_Data_haptic_Warning_Threshold_Yellow_to_Red
        enable-take-address=true, indirect-api=false, port=DataServices_Obsolescence_Data_Read_Obsolescence_Data_PRE_SAFE_Lvl_4_5_Threshold_Green_to_Yellow
        enable-take-address=true, indirect-api=false, port=DataServices_Obsolescence_Data_Read_Obsolescence_Data_BSR_Threshold_Yellow_to_Red
        enable-take-address=true, indirect-api=false, port=DataServices_Obsolescence_Data_Read_Obsolescence_Data_haptic_Warning_Threshold_Green_to_Yellow
        enable-take-address=true, indirect-api=false, port=DataServices_Obsolescence_Data_Read_Obsolescence_Data_BSR_Current_Value
        enable-take-address=true, indirect-api=false, port=DataServices_Obsolescence_Data_Read_Obsolescence_Data_PRE_CRASH_Threshold_Yellow_to_Red
        enable-take-address=true, indirect-api=false, port=DataServices_Obsolescence_Data_Read_Obsolescence_Data_PRE_SAFE_Lvl_4_5_Threshold_Yellow_to_Red
        enable-take-address=true, indirect-api=false, port=DataServices_Obsolescence_Data_Read_Obsolescence_Data_PRE_CRASH_Threshold_Green_to_Yellow
        enable-take-address=true, indirect-api=false, port=DataServices_Obsolescence_Data_Read_Obsolescence_Data_PRE_SAFE_Lvl_4_5_Current_Value
        enable-take-address=true, indirect-api=false, port=DataServices_Obsolescence_Data_Read_Obsolescence_Data_haptic_Warning_Current_Value
        enable-take-address=true, indirect-api=false, port=DataServices_Obsolescence_Data_Read_Obsolescence_Data_BSR_Threshold_Green_to_Yellow
        enable-take-address=true, indirect-api=false, port=DataServices_Obsolescence_Data_Read_Obsolescence_Data_PRE_CRASH_Current_Value
        enable-take-address=true, indirect-api=false, port=DataServices_Availability_Data_Read_Availability_Data_PRE_SAFE_haptic_warning
        enable-take-address=true, indirect-api=false, port=DataServices_PRE_SAFE_Recorder_1_read_Read_CombinedDataElement
        enable-take-address=true, indirect-api=false, port=DataServices_Minimum_Software_Version_Read_Minimum_Software_Version
        enable-take-address=true, indirect-api=false, port=DataServices_Tensioning_Cycle_BSR_Read_CombinedSignal
        enable-take-address=true, indirect-api=false, port=DataServices_VINDataIdentifier_Read_VINDataIdentifier
        enable-take-address=true, indirect-api=false, port=DataServices_Diagnostic_User_Role_Read_Cebas_UserRole
        enable-take-address=true, indirect-api=false, port=DataServices_Secured_System_Date_and_Time_Read_GeneralizedTime
        enable-take-address=true, indirect-api=false, port=DataServices_BootSoftwareVersion_Read_Boot_SW_year
        enable-take-address=true, indirect-api=false, port=DataServices_BootSoftwareVersion_Read_Boot_SW_patch_level
        enable-take-address=true, indirect-api=false, port=DataServices_BootSoftwareVersion_Read_Boot_SW_week
        enable-take-address=true, indirect-api=false, port=DataServices_Reprogramming_Attempt_Counter_Read_Reprogramming_Attempts
        enable-take-address=true, indirect-api=false, port=DataServices_Standard_Application_SW_Package_Information_Read_Standard_Application_SW_Package_Major_Version
        enable-take-address=true, indirect-api=false, port=DataServices_Standard_Application_SW_Package_Information_Read_Standard_Application_SW_Package_Patch_Level
        enable-take-address=true, indirect-api=false, port=DataServices_Standard_Application_SW_Package_Information_Read_Standard_Application_SW_Package_Minor_Version
        enable-take-address=true, indirect-api=false, port=DataServices_Standard_Application_SW_Package_Information_Read_Supplier_Identification
        enable-take-address=true, indirect-api=false, port=DataServices_Standard_Application_SW_Package_Information_Read_Standard_Application_SW_Package_Build_Version
        enable-take-address=true, indirect-api=false, port=DataServices_Standard_Application_SW_Package_Information_Read_AUTOSAR_Platform
        enable-take-address=true, indirect-api=false, port=DataServices_Standard_Application_SW_Package_Information_Read_C_P_Identification
        enable-take-address=true, indirect-api=false, port=DataServices_Dump_of_Vedoc_Relevant_Information_Read_PatchedObject
        enable-take-address=true, indirect-api=false, port=DataServices_ECU_Name_Read_Diagnostic_ECU_Name
        enable-take-address=true, indirect-api=false, port=DataServices_Security_Event_Log_Read_Security_Event_Log
        enable-take-address=true, indirect-api=false, port=DataServices_Adjust_ISO_15765_2_Block_Size_and_STmin_Parameter_Read_STmin_Value_as_defined_in_ISO_15765_2
        enable-take-address=true, indirect-api=false, port=DataServices_Adjust_ISO_15765_2_Block_Size_and_STmin_Parameter_Read_Block_Size_Value_as_defined_in_ISO_15765_2
        enable-take-address=true, indirect-api=false, port=DataServices_SSA_Version_Information_Read_SSA_Patch_Level
        enable-take-address=true, indirect-api=false, port=DataServices_SSA_Version_Information_Read_SSA_Major_Version
        enable-take-address=true, indirect-api=false, port=DataServices_SSA_Version_Information_Read_SSA_Minor_Version
        enable-take-address=true, indirect-api=false, port=DataServices_SoftwareSupplier_Read_Software_Logical_Block_Supplier_Identification
        enable-take-address=true, indirect-api=false, port=DataServices_DDS_Package_Release_Read_DDS_Package_Release_of_Boot_Software_Month_Boot
        enable-take-address=true, indirect-api=false, port=DataServices_DDS_Package_Release_Read_DDS_Package_Release_of_Application_Software_Year_Appl
        enable-take-address=true, indirect-api=false, port=DataServices_DDS_Package_Release_Read_DDS_Package_Release_of_Application_Software_Month_Appl
        enable-take-address=true, indirect-api=false, port=DataServices_DDS_Package_Release_Read_DDS_Package_Release_of_Boot_Software_Year_Boot
        enable-take-address=true, indirect-api=false, port=DataServices_Security_Event_Log_Current_Counter_Values_Read_Security_Event_Log_Current_Counter_Values
        enable-take-address=true, indirect-api=false, port=DataServices_Supported_configuration_mechanisms_Read_Config_mechanisms
        enable-take-address=true, indirect-api=false, port=DataServices_Calibration_Identifications_CAL_ID_Read_Calibration_Identification
        enable-take-address=true, indirect-api=false, port=DataServices_CAN_input_Read_Neues_Bitfeld_6
        enable-take-address=true, indirect-api=false, port=DataServices_CAN_input_Read_Neues_Bitfeld_5
        enable-take-address=true, indirect-api=false, port=DataServices_CAN_input_Read_Neues_Bitfeld_4
        enable-take-address=true, indirect-api=false, port=DataServices_CAN_input_Read_Neues_Bitfeld_3
        enable-take-address=true, indirect-api=false, port=DataServices_CAN_input_Read_Supply_battery_voltage
        enable-take-address=true, indirect-api=false, port=DataServices_CAN_input_Read_Neues_Bitfeld_2
        enable-take-address=true, indirect-api=false, port=DataServices_CAN_input_Read_Neues_Bitfeld_1
        enable-take-address=true, indirect-api=false, port=DataServices_CAN_input_Read_Neues_Bitfeld_8
        enable-take-address=true, indirect-api=false, port=DataServices_CAN_input_Read_Neues_Bitfeld_7
        enable-take-address=true, indirect-api=false, port=DataServices_SecOC_Vehicle_Shared_Secret_Hash_Read_SecOC_Vehicle_Shared_Secret_Hash
        enable-take-address=true, indirect-api=false, port=DataServices_Trust_model_ECU_CSR_Read_Trust_model_ECU_CSR
        enable-take-address=true, indirect-api=false, port=DataServices_Root_CA_Certificate_Read_Root_CA_Certificate
        enable-take-address=true, indirect-api=false, port=DataServices_ECUSerialNumberDataIdentifier_Read_ECU_Serial_Number
        enable-take-address=true, indirect-api=false, port=DataServices_VIN_Status_Read_VIN_Lock_Status
        enable-take-address=true, indirect-api=false, port=DataServices_VIN_Status_Read_VIN_Status
        enable-take-address=true, indirect-api=false, port=DataServices_Release_Cycles_BSR_and_PreSafe_Read_CombinedSignal
        enable-take-address=true, indirect-api=false, port=DataServices_Status_SSA_Pre_Compile_Switches_Read_Precompile_switch
        enable-take-address=true, indirect-api=false, port=DataServices_PRE_SAFE_Recorder_2_read_Read_CombinedDataElement
        enable-take-address=true, indirect-api=false, port=DataServices_BSR_Counter_read_Read_BSR_Counter
        enable-take-address=true, indirect-api=false, port=DataServices_Vehicle_Odometer_in_Low_Resolution_Read_Vehicle_Odometer_in_Low_Resolution
        enable-take-address=true, indirect-api=false, port=DataServices_HardwareSupplier_Read_Hardware_Supplier_Identification
        enable-take-address=true, indirect-api=false, port=DataServices_MercedesCarGroupSoftware_Read_Software_Logical_Block_Numbers
        enable-take-address=true, indirect-api=false, port=DataServices_SecOC_PDU_Data_IDs_and_Key_CMACs_Read_Secured_PDU_Data_IDs_and_Key_CMACs
        enable-take-address=true, indirect-api=false, port=DataServices_Current_Operating_Time_Read_Current_Operating_Time
        enable-take-address=true, indirect-api=false, port=DataServices_Current_Operating_Time_Read_Operating_Time_Status
        enable-take-address=true, indirect-api=false, port=DataServices_Global_Time_Sync_Measured_Values_Read_GTSM
        enable-take-address=true, indirect-api=false, port=DataServices_Trust_model_Root_CA_certificate_Read_Trust_model_Root_CA_certificate
        enable-take-address=true, indirect-api=false, port=DataServices_RandomNumber_Read_Generated_Random_Number_Result
        enable-take-address=true, indirect-api=false, port=DataServices_RandomNumber_Read_Generated_Random_Number
        enable-take-address=true, indirect-api=false, port=DataServices_MercedesCarGroupHardware_Read_Hardware_Part_Number
        enable-take-address=true, indirect-api=false, port=DataServices_Internal_ECU_information_Read_ECU_Temperature
        enable-take-address=true, indirect-api=false, port=DataServices_Internal_ECU_information_Read_MOTOR_Current
        enable-take-address=true, indirect-api=false, port=DataServices_Internal_ECU_information_Read_Autosar_System_State_EcuM_State
        enable-take-address=true, indirect-api=false, port=DataServices_Backend_CA_Certificate_Read_Backend_CA_Certificate
        enable-take-address=true, indirect-api=false, port=DataServices_Trust_model_Intermediate_CA_certificate_Read_Trust_model_Intermediate_CA_Certificate
        enable-take-address=true, indirect-api=false, port=DataServices_Diagnostic_Authentication_Certificate_Identification_Read_Diagnostic_Authentication_Certificate_Serial_Number
        enable-take-address=true, indirect-api=false, port=DataServices_Diagnostic_Authentication_Certificate_Identification_Read_Diagnostic_Authentication_Certificate_Issuer
        enable-take-address=true, indirect-api=false, port=DataServices_SecOC_PDU_Data_IDs_and_Key_Checksum_Read_Secured_PDU_Data_IDs_and_Key_Checksum
        enable-take-address=true, indirect-api=false, port=DataServices_PreSafe_Cycles_Level_1_8_Read_CombinedSignal
        enable-take-address=true, indirect-api=false, port=DataServices_System_Time_read_Read_System_time
        enable-take-address=true, indirect-api=false, port=DataServices_Trust_Model_Request_ephemeral_public_key_Read_Data_Signature
        enable-take-address=true, indirect-api=false, port=DataServices_Trust_Model_Request_ephemeral_public_key_Read_Ephemeral_ECU_Public_Key
        enable-take-address=true, indirect-api=false, port=DataServices_Trust_Model_Request_ephemeral_public_key_Read_Certificates
        enable-take-address=true, indirect-api=false, port=DataServices_Trust_Model_Request_ephemeral_public_key_Read_Nonce
        enable-take-address=true, indirect-api=false, port=DataServices_HW_input_Read_Voltage_KL30t
        enable-take-address=true, indirect-api=false, port=DataServices_HW_input_Read_Voltage_Motor
        enable-take-address=true, indirect-api=false, port=DataServices_Diagnostic_Trace_Memory_Read_Diagnostic_Trace_Memory
        enable-take-address=true, indirect-api=false, port=DataServices_ReadFingerprint_Read_Software_Fingerprint_s
        enable-take-address=true, indirect-api=false, port=DataServices_Trust_model_full_chain_of_trust_certificates_Read_Trust_model_certificates
        enable-take-address=true, indirect-api=false, port=DataServices_ZZZ_Vehicle_Equipment_Development_Read_Zykluszeit_Messtechnik
        enable-take-address=true, indirect-api=false, port=DataServices_ZZZ_Vehicle_Equipment_Development_Read_Bitfield
        enable-take-address=true, indirect-api=false, port=DataServices_PRE_SAFE_Counter_read_Read_CombinedDataElement
        enable-take-address=true, indirect-api=false, port=DataServices_Trust_model_Backend_CA_certificate_Read_Trust_model_Backend_CA_certificate
        enable-take-address=true, indirect-api=false, port=DataServices_ActiveDiagnosticInformation_Read_Session
        enable-take-address=true, indirect-api=false, port=DataServices_ActiveDiagnosticInformation_Read_Identification
        enable-take-address=true, indirect-api=false, port=DataServices_Real_Time_Offset_Read_TickCount
        enable-take-address=true, indirect-api=false, port=DataServices_Real_Time_Offset_Read_Real_Time_Offset
        enable-take-address=true, indirect-api=false, port=DataServices_SoftwareVersion_Read_Software_Logical_Block_Version_Information
        enable-take-address=true, indirect-api=false, port=DataServices_CAN_output_Read_CANoutput1
        enable-take-address=true, indirect-api=false, port=DataServices_CAN_output_Read_PS_Curve_XX_Stat_ST3
        enable-take-address=true, indirect-api=false, port=DataServices_CAN_output_Read_RBTMxx_Actv_Lvl_ST35
        enable-take-address=true, indirect-api=false, port=DataServices_CAN_output_Read_RBTMxx_SP_ActvClient_ST35
        enable-take-address=true, indirect-api=false, port=DataServices_CAN_output_Read_RBTMxx_SP_FctPrecond_Stat_ST35
        enable-take-address=true, indirect-api=false, port=DataServices_Access_Control_List_Version_Read_Basic_ACL_Version_Generation_Time_GTC
        enable-take-address=true, indirect-api=false, port=DataServices_Access_Control_List_Version_Read_ECU_indvidual_ACL_Version_Generation_Time_GTC
        enable-take-address=true, indirect-api=false, port=DataServices_Access_Control_List_Version_Read_Basic_ACL_Hash
        enable-take-address=true, indirect-api=false, port=DataServices_Access_Control_List_Version_Read_Basic_ACL_Version_Candela_File_Version_Patch
        enable-take-address=true, indirect-api=false, port=DataServices_Access_Control_List_Version_Read_ECU_indvidual_ACL_Version_Candela_File_Version_Patch
        enable-take-address=true, indirect-api=false, port=DataServices_Access_Control_List_Version_Read_ECU_indvidual_ACL_Hash
        enable-take-address=true, indirect-api=false, port=DataServices_Access_Control_List_Version_Read_ECU_indvidual_ACL_Version_Candela_File_Version_Minor
        enable-take-address=true, indirect-api=false, port=DataServices_Access_Control_List_Version_Read_ECU_indvidual_ACL_Version_Candela_File_Version_Major
        enable-take-address=true, indirect-api=false, port=DataServices_Access_Control_List_Version_Read_Basic_ACL_Version_Candela_File_Version_Minor
        enable-take-address=true, indirect-api=false, port=DataServices_Access_Control_List_Version_Read_Basic_ACL_Version_Candela_File_Version_Major
        enable-take-address=true, indirect-api=false, port=DataServices_SecOC_Local_TickCount_Read_TickCount
        enable-take-address=true, indirect-api=false, port=DataServices_HardwareVersion_Read_HW_year
        enable-take-address=true, indirect-api=false, port=DataServices_HardwareVersion_Read_HW_week
        enable-take-address=true, indirect-api=false, port=DataServices_HardwareVersion_Read_HW_patch_level
        enable-take-address=true, indirect-api=false, port=DataServices_ECU_Location_Read_Side_Allocation
        enable-take-address=true, indirect-api=false, port=DataServices_Cycle_configuration_Read_Cycles
        enable-take-address=true, indirect-api=false, port=DataServices_Steps_library_Read_Steps
        enable-take-address=true, indirect-api=false, port=DataServices_Trust_Model_Root_Replacement_Key_Read_Root_Replacement_Key
        enable-take-address=true, indirect-api=false, port=DataServices_Last_Warm_Reset_Parameters_Read_Reset_Cause_Counter
        enable-take-address=true, indirect-api=false, port=DataServices_Last_Warm_Reset_Parameters_Read_Last_Detected_Warm_Reset_Cause
        enable-take-address=true, indirect-api=false, port=DataServices_Measurement_Frames_Configuration_Read_CombinedSignal
        enable-take-address=true, indirect-api=false, port=DataServices_Measurement_Frame_Block_12_Config_Read_CombinedSignal
        enable-take-address=true, indirect-api=false, port=DataServices_HB_Calibration_Read_CombinedSignal
        enable-take-address=true, indirect-api=false, port=DataServices_AEC_Status_Read_AEC_Status
        enable-take-address=true, indirect-api=false, port=DataServices_Reset_Cause_Management_Read_Reset_Cause
        enable-take-address=true, indirect-api=false, port=DataServices_Task_Response_Time_Read_Task_histograms
        enable-take-address=true, indirect-api=false, port=DataServices_Stack_Load_Read_Maximum
        enable-take-address=true, indirect-api=false, port=DataServices_CPU_Load_Read_CPU_load_histograms
        enable-take-address=true, indirect-api=false, port=DataServices_Memory_Usage_Cycles_Read_Memory_Usage_Cycles
        enable-take-address=true, indirect-api=false, port=DataServices_HSM_Identification_Read_HSM_MB_Version_HW_patch_level
        enable-take-address=true, indirect-api=false, port=DataServices_HSM_Identification_Read_HSM_MB_Supplier_Version_HW_week
        enable-take-address=true, indirect-api=false, port=DataServices_HSM_Identification_Read_HSM_MB_Supplier_Version_HW_patch_level
        enable-take-address=true, indirect-api=false, port=DataServices_HSM_Identification_Read_HSM_MB_Version_HW_year
        enable-take-address=true, indirect-api=false, port=DataServices_HSM_Identification_Read_HSM_MB_Partnumber
        enable-take-address=true, indirect-api=false, port=DataServices_HSM_Identification_Read_HSM_MB_Supplier_Version_HW_year
        enable-take-address=true, indirect-api=false, port=DataServices_HSM_Identification_Read_HSM_MB_Version_HW_week
        enable-take-address=true, indirect-api=false, port=DataServices_SW_Version_Read_SW_Version
        enable-take-address=true, indirect-api=false, port=DataServices_Hardware_Version_Information_Write_HW_year
        enable-take-address=true, indirect-api=false, port=DataServices_Hardware_Version_Information_Write_HW_week
        enable-take-address=true, indirect-api=false, port=DataServices_Hardware_Version_Information_Write_HW_patch_level
        enable-take-address=true, indirect-api=false, port=DataServices_Calibration_Identifications_CAL_ID_Write_Calibration_Identification
        enable-take-address=true, indirect-api=false, port=DataServices_Calibration_Identifications_CAL_ID_Write_Number_of_data_items
        enable-take-address=true, indirect-api=false, port=DataServices_ECU_serial_number_Read_PCBA_Programmed_Part_number
        enable-take-address=true, indirect-api=false, port=DataServices_ECU_serial_number_Read_ECU_traceability_number
        enable-take-address=true, indirect-api=false, port=RoutineServices_Routine_Erase_All_Start
        enable-take-address=true, indirect-api=false, port=RoutineServices_Routine_Force_External_WDG_Start
        enable-take-address=true, indirect-api=false, port=DataServices_Customer_Settings_Read_BltSlckDec_Md_Stat
        enable-take-address=true, indirect-api=false, port=DataServices_Customer_Settings_Read_PS_Curve_Stat
        enable-take-address=true, indirect-api=false, port=DataServices_Trust_Model_CSR_Supplier_Signature_Read_Trust_Model_CSR_Supplier_Signature
        enable-take-address=true, indirect-api=false, port=DataServices_Velocity_PI_Regulation_Coefficient_Read_Input_Velocity_Coefficient
        enable-take-address=true, indirect-api=false, port=DataServices_Temperature_Sensor_Calibration_Point_Read_Offset_Point
      6 x runnable:
        Dcm_MainFunction
          6 x mode switch point:
            ModeSwitchPointDcm_MainFunction_DcmControlDtcSetting_DcmControlDtcSetting: mode-group=DcmControlDtcSetting.DcmControlDtcSetting
            ModeSwitchPointDcm_MainFunction_DcmEcuReset_DcmEcuReset: mode-group=DcmEcuReset.DcmEcuReset
            ModeSwitchPointDcm_MainFunction_DcmModeRapidPowerShutDown_DcmModeRapidPowerShutDown: mode-group=DcmModeRapidPowerShutDown.DcmModeRapidPowerShutDown
            ModeSwitchPointDcm_MainFunction_DcmDiagnosticSessionControl_DcmDiagnosticSessionControl: mode-group=DcmDiagnosticSessionControl.DcmDiagnosticSessionControl
            ModeSwitchPointDcm_MainFunction_DcmCommunicationControl_ComMConf_ComMChannel_RBTM_FL_BODY3_8uqv9blm85ehm0msat385m76v_03_621c1019: mode-group=DcmCommunicationControl_ComMConf_ComMChannel_RBTM_FL_BODY3_8uqv9blm85ehm0msat385m76v_03d5f5f6.DcmCommunicationControl_ComMConf_ComMChannel_RBTM_FL_BODY3_8uqv9blm85ehm0msat385m76v_03d5f5f6
            ModeSwitchPointDcm_MainFunction_DcmCommunicationControl_ComMConf_ComMChannel_RBTM_FR_BODY3_4xwwtd59665s787n6ctawh7k8_23_185dfe5b: mode-group=DcmCommunicationControl_ComMConf_ComMChannel_RBTM_FR_BODY3_4xwwtd59665s787n6ctawh7k8_23a94727.DcmCommunicationControl_ComMConf_ComMChannel_RBTM_FR_BODY3_4xwwtd59665s787n6ctawh7k8_23a94727
          472 x sync call, all with timeout=0:
            OpServerCallDcm_MainFunction_Start_RoutineServices_Routine_Check_Reprogramming_Preconditions_Start: operation=RoutineServices_Routine_Check_Reprogramming_Preconditions_Start.Start
            OpServerCallDcm_MainFunction_Start_RoutineServices_Routine_PreCheckProgrammingDependencies_Start: operation=RoutineServices_Routine_PreCheckProgrammingDependencies_Start.Start
            OpServerCallDcm_MainFunction_Start_RoutineServices_Routine_Reset_VINDataIdentifier_Start: operation=RoutineServices_Routine_Reset_VINDataIdentifier_Start.Start
            OpServerCallDcm_MainFunction_Start_RoutineServices_Routine_Synchronize_to_Non_volatile_Memory_Start: operation=RoutineServices_Routine_Synchronize_to_Non_volatile_Memory_Start.Start
            OpServerCallDcm_MainFunction_Stop_RoutineServices_Routine_Synchronize_to_Non_volatile_Memory_Start: operation=RoutineServices_Routine_Synchronize_to_Non_volatile_Memory_Start.Stop
            OpServerCallDcm_MainFunction_RequestResults_RoutineServices_Routine_Synchronize_to_Non_volatile_Memory_Start: operation=RoutineServices_Routine_Synchronize_to_Non_volatile_Memory_Start.RequestResults
            OpServerCallDcm_MainFunction_Start_RoutineServices_Routine_Authenticate_Diagnostic_User_or_Tester_Start: operation=RoutineServices_Routine_Authenticate_Diagnostic_User_or_Tester_Start.Start
            OpServerCallDcm_MainFunction_Start_RoutineServices_Routine_Enhance_Access_Rights_Start: operation=RoutineServices_Routine_Enhance_Access_Rights_Start.Start
            OpServerCallDcm_MainFunction_Start_RoutineServices_Routine_Evaluate_Data_Verification_Certificate_Start: operation=RoutineServices_Routine_Evaluate_Data_Verification_Certificate_Start.Start
            OpServerCallDcm_MainFunction_Start_RoutineServices_Routine_Verify_Signature_Start: operation=RoutineServices_Routine_Verify_Signature_Start.Start
            OpServerCallDcm_MainFunction_Start_RoutineServices_Routine_Replace_Certificates_Start: operation=RoutineServices_Routine_Replace_Certificates_Start.Start
            OpServerCallDcm_MainFunction_Start_RoutineServices_Routine_Synchronize_Secured_System_Date_and_Time_Start: operation=RoutineServices_Routine_Synchronize_Secured_System_Date_and_Time_Start.Start
            OpServerCallDcm_MainFunction_Start_RoutineServices_Routine_Certificate_Self_Check_Start: operation=RoutineServices_Routine_Certificate_Self_Check_Start.Start
            OpServerCallDcm_MainFunction_Start_RoutineServices_Routine_Replace_Trust_model_Certificates_Start: operation=RoutineServices_Routine_Replace_Trust_model_Certificates_Start.Start
            OpServerCallDcm_MainFunction_Start_RoutineServices_Routine_Replace_Trust_model_Root_Certificate_Start: operation=RoutineServices_Routine_Replace_Trust_model_Root_Certificate_Start.Start
            OpServerCallDcm_MainFunction_Start_RoutineServices_Routine_Trust_Model_SecOC_ECU_Shared_Secret_Distribution_Start: operation=RoutineServices_Routine_Trust_Model_SecOC_ECU_Shared_Secret_Distribution_Start.Start
            OpServerCallDcm_MainFunction_Start_RoutineServices_Routine_Trust_Model_Generate_Key_Pair_Start: operation=RoutineServices_Routine_Trust_Model_Generate_Key_Pair_Start.Start
            OpServerCallDcm_MainFunction_Start_RoutineServices_Routine_Get_Certificate_Entry_Start: operation=RoutineServices_Routine_Get_Certificate_Entry_Start.Start
            OpServerCallDcm_MainFunction_ReadData_DataServices_DID_0131_SAR_Data_Storage_Status: operation=DataServices_DID_0131_SAR_Data_Storage_Status.ReadData
            OpServerCallDcm_MainFunction_ConditionCheckRead_DataServices_DID_0131_SAR_Data_Storage_Status: operation=DataServices_DID_0131_SAR_Data_Storage_Status.ConditionCheckRead
            OpServerCallDcm_MainFunction_WriteData_DataServices_DID_0131_SAR_Data_Storage_Status: operation=DataServices_DID_0131_SAR_Data_Storage_Status.WriteData
            OpServerCallDcm_MainFunction_ReadData_DataServices_DID_0136_Trigger_Event_Activation_Status_Byte_2: operation=DataServices_DID_0136_Trigger_Event_Activation_Status_Byte_2.ReadData
            OpServerCallDcm_MainFunction_ConditionCheckRead_DataServices_DID_0136_Trigger_Event_Activation_Status_Byte_2: operation=DataServices_DID_0136_Trigger_Event_Activation_Status_Byte_2.ConditionCheckRead
            OpServerCallDcm_MainFunction_WriteData_DataServices_DID_0136_Trigger_Event_Activation_Status_Byte_2: operation=DataServices_DID_0136_Trigger_Event_Activation_Status_Byte_2.WriteData
            OpServerCallDcm_MainFunction_ReadData_DataServices_DID_0136_Trigger_Event_Activation_Status_Byte_1: operation=DataServices_DID_0136_Trigger_Event_Activation_Status_Byte_1.ReadData
            OpServerCallDcm_MainFunction_ConditionCheckRead_DataServices_DID_0136_Trigger_Event_Activation_Status_Byte_1: operation=DataServices_DID_0136_Trigger_Event_Activation_Status_Byte_1.ConditionCheckRead
            OpServerCallDcm_MainFunction_WriteData_DataServices_DID_0136_Trigger_Event_Activation_Status_Byte_1: operation=DataServices_DID_0136_Trigger_Event_Activation_Status_Byte_1.WriteData
            OpServerCallDcm_MainFunction_ReadData_DataServices_Diagnostic_Extract_Version_Read_Diagnostic_Extract_Minor_Version: operation=DataServices_Diagnostic_Extract_Version_Read_Diagnostic_Extract_Minor_Version.ReadData
            OpServerCallDcm_MainFunction_ConditionCheckRead_DataServices_Diagnostic_Extract_Version_Read_Diagnostic_Extract_Minor_Version: operation=DataServices_Diagnostic_Extract_Version_Read_Diagnostic_Extract_Minor_Version.ConditionCheckRead
            OpServerCallDcm_MainFunction_ReadData_DataServices_Diagnostic_Extract_Version_Read_CANdela_Version: operation=DataServices_Diagnostic_Extract_Version_Read_CANdela_Version.ReadData
            OpServerCallDcm_MainFunction_ConditionCheckRead_DataServices_Diagnostic_Extract_Version_Read_CANdela_Version: operation=DataServices_Diagnostic_Extract_Version_Read_CANdela_Version.ConditionCheckRead
            OpServerCallDcm_MainFunction_ReadData_DataServices_Diagnostic_Extract_Version_Read_Diagnostic_Extract_Major_Version: operation=DataServices_Diagnostic_Extract_Version_Read_Diagnostic_Extract_Major_Version.ReadData
            OpServerCallDcm_MainFunction_ConditionCheckRead_DataServices_Diagnostic_Extract_Version_Read_Diagnostic_Extract_Major_Version: operation=DataServices_Diagnostic_Extract_Version_Read_Diagnostic_Extract_Major_Version.ConditionCheckRead
            OpServerCallDcm_MainFunction_ReadData_DataServices_Diagnostic_Extract_Version_Read_DDM_Version: operation=DataServices_Diagnostic_Extract_Version_Read_DDM_Version.ReadData
            OpServerCallDcm_MainFunction_ConditionCheckRead_DataServices_Diagnostic_Extract_Version_Read_DDM_Version: operation=DataServices_Diagnostic_Extract_Version_Read_DDM_Version.ConditionCheckRead
            OpServerCallDcm_MainFunction_ReadData_DataServices_Diagnostic_Extract_Version_Read_Exported_Diagnostic_Variant: operation=DataServices_Diagnostic_Extract_Version_Read_Exported_Diagnostic_Variant.ReadData
            OpServerCallDcm_MainFunction_ConditionCheckRead_DataServices_Diagnostic_Extract_Version_Read_Exported_Diagnostic_Variant: operation=DataServices_Diagnostic_Extract_Version_Read_Exported_Diagnostic_Variant.ConditionCheckRead
            OpServerCallDcm_MainFunction_ReadData_DataServices_Diagnostic_Extract_Version_Read_Diagnostic_Extract_Patch_Version: operation=DataServices_Diagnostic_Extract_Version_Read_Diagnostic_Extract_Patch_Version.ReadData
            OpServerCallDcm_MainFunction_ConditionCheckRead_DataServices_Diagnostic_Extract_Version_Read_Diagnostic_Extract_Patch_Version: operation=DataServices_Diagnostic_Extract_Version_Read_Diagnostic_Extract_Patch_Version.ConditionCheckRead
            OpServerCallDcm_MainFunction_ReadData_DataServices_Vehicle_Equipment_Read_Equipment_1: operation=DataServices_Vehicle_Equipment_Read_Equipment_1.ReadData
            OpServerCallDcm_MainFunction_ConditionCheckRead_DataServices_Vehicle_Equipment_Read_Equipment_1: operation=DataServices_Vehicle_Equipment_Read_Equipment_1.ConditionCheckRead
            OpServerCallDcm_MainFunction_WriteData_DataServices_Vehicle_Equipment_Read_Equipment_1: operation=DataServices_Vehicle_Equipment_Read_Equipment_1.WriteData
            OpServerCallDcm_MainFunction_ReadData_DataServices_Vehicle_Equipment_Read_Unterspannungsbereichsschwelle: operation=DataServices_Vehicle_Equipment_Read_Unterspannungsbereichsschwelle.ReadData
            OpServerCallDcm_MainFunction_ConditionCheckRead_DataServices_Vehicle_Equipment_Read_Unterspannungsbereichsschwelle: operation=DataServices_Vehicle_Equipment_Read_Unterspannungsbereichsschwelle.ConditionCheckRead
            OpServerCallDcm_MainFunction_WriteData_DataServices_Vehicle_Equipment_Read_Unterspannungsbereichsschwelle: operation=DataServices_Vehicle_Equipment_Read_Unterspannungsbereichsschwelle.WriteData
            OpServerCallDcm_MainFunction_ReadData_DataServices_Vehicle_Equipment_Read_Unterspannungsabbruchschwelle: operation=DataServices_Vehicle_Equipment_Read_Unterspannungsabbruchschwelle.ReadData
            OpServerCallDcm_MainFunction_ConditionCheckRead_DataServices_Vehicle_Equipment_Read_Unterspannungsabbruchschwelle: operation=DataServices_Vehicle_Equipment_Read_Unterspannungsabbruchschwelle.ConditionCheckRead
            OpServerCallDcm_MainFunction_WriteData_DataServices_Vehicle_Equipment_Read_Unterspannungsabbruchschwelle: operation=DataServices_Vehicle_Equipment_Read_Unterspannungsabbruchschwelle.WriteData
            OpServerCallDcm_MainFunction_ReadData_DataServices_Vehicle_Equipment_Read_Ueberspannungsbereichsschwelle: operation=DataServices_Vehicle_Equipment_Read_Ueberspannungsbereichsschwelle.ReadData
            OpServerCallDcm_MainFunction_ConditionCheckRead_DataServices_Vehicle_Equipment_Read_Ueberspannungsbereichsschwelle: operation=DataServices_Vehicle_Equipment_Read_Ueberspannungsbereichsschwelle.ConditionCheckRead
            OpServerCallDcm_MainFunction_WriteData_DataServices_Vehicle_Equipment_Read_Ueberspannungsbereichsschwelle: operation=DataServices_Vehicle_Equipment_Read_Ueberspannungsbereichsschwelle.WriteData
            OpServerCallDcm_MainFunction_ReadData_DataServices_Vehicle_Equipment_Read_Equipment_3: operation=DataServices_Vehicle_Equipment_Read_Equipment_3.ReadData
            OpServerCallDcm_MainFunction_ConditionCheckRead_DataServices_Vehicle_Equipment_Read_Equipment_3: operation=DataServices_Vehicle_Equipment_Read_Equipment_3.ConditionCheckRead
            OpServerCallDcm_MainFunction_WriteData_DataServices_Vehicle_Equipment_Read_Equipment_3: operation=DataServices_Vehicle_Equipment_Read_Equipment_3.WriteData
            OpServerCallDcm_MainFunction_ReadData_DataServices_Vehicle_Equipment_Read_Equipment_2: operation=DataServices_Vehicle_Equipment_Read_Equipment_2.ReadData
            OpServerCallDcm_MainFunction_ConditionCheckRead_DataServices_Vehicle_Equipment_Read_Equipment_2: operation=DataServices_Vehicle_Equipment_Read_Equipment_2.ConditionCheckRead
            OpServerCallDcm_MainFunction_WriteData_DataServices_Vehicle_Equipment_Read_Equipment_2: operation=DataServices_Vehicle_Equipment_Read_Equipment_2.WriteData
            OpServerCallDcm_MainFunction_ReadData_DataServices_Vehicle_Equipment_Read_Ueberspannungsabbruchschwelle: operation=DataServices_Vehicle_Equipment_Read_Ueberspannungsabbruchschwelle.ReadData
            OpServerCallDcm_MainFunction_ConditionCheckRead_DataServices_Vehicle_Equipment_Read_Ueberspannungsabbruchschwelle: operation=DataServices_Vehicle_Equipment_Read_Ueberspannungsabbruchschwelle.ConditionCheckRead
            OpServerCallDcm_MainFunction_WriteData_DataServices_Vehicle_Equipment_Read_Ueberspannungsabbruchschwelle: operation=DataServices_Vehicle_Equipment_Read_Ueberspannungsabbruchschwelle.WriteData
            OpServerCallDcm_MainFunction_ReadData_DataServices_Backend_CA_Certificate_Identification_Read_Backend_CA_SubjectKeyIdentifier: operation=DataServices_Backend_CA_Certificate_Identification_Read_Backend_CA_SubjectKeyIdentifier.ReadData
            OpServerCallDcm_MainFunction_ConditionCheckRead_DataServices_Backend_CA_Certificate_Identification_Read_Backend_CA_Subj_d7dc6de7: operation=DataServices_Backend_CA_Certificate_Identification_Read_Backend_CA_SubjectKeyIdentifier.ConditionCheckRead
            OpServerCallDcm_MainFunction_ReadData_DataServices_Trust_model_ECU_certificate_Read_Trust_model_ECU_Certificate: operation=DataServices_Trust_model_ECU_certificate_Read_Trust_model_ECU_Certificate.ReadData
            OpServerCallDcm_MainFunction_ReadDataLength_DataServices_Trust_model_ECU_certificate_Read_Trust_model_ECU_Certificate: operation=DataServices_Trust_model_ECU_certificate_Read_Trust_model_ECU_Certificate.ReadDataLength
            OpServerCallDcm_MainFunction_ConditionCheckRead_DataServices_Trust_model_ECU_certificate_Read_Trust_model_ECU_Certificate: operation=DataServices_Trust_model_ECU_certificate_Read_Trust_model_ECU_Certificate.ConditionCheckRead
            OpServerCallDcm_MainFunction_ReadData_DataServices_Seatbelt_Serial_Number_Read_Unique_Seatbelt_Serialnumber: operation=DataServices_Seatbelt_Serial_Number_Read_Unique_Seatbelt_Serialnumber.ReadData
            OpServerCallDcm_MainFunction_ConditionCheckRead_DataServices_Seatbelt_Serial_Number_Read_Unique_Seatbelt_Serialnumber: operation=DataServices_Seatbelt_Serial_Number_Read_Unique_Seatbelt_Serialnumber.ConditionCheckRead
            OpServerCallDcm_MainFunction_ReadData_DataServices_PRE_SAFE_Recorder_1_read_Read_CombinedDataElement: operation=DataServices_PRE_SAFE_Recorder_1_read_Read_CombinedDataElement.ReadData
            OpServerCallDcm_MainFunction_ReadDataLength_DataServices_PRE_SAFE_Recorder_1_read_Read_CombinedDataElement: operation=DataServices_PRE_SAFE_Recorder_1_read_Read_CombinedDataElement.ReadDataLength
            OpServerCallDcm_MainFunction_ConditionCheckRead_DataServices_PRE_SAFE_Recorder_1_read_Read_CombinedDataElement: operation=DataServices_PRE_SAFE_Recorder_1_read_Read_CombinedDataElement.ConditionCheckRead
            OpServerCallDcm_MainFunction_WriteData_DataServices_PRE_SAFE_Recorder_1_read_Read_CombinedDataElement: operation=DataServices_PRE_SAFE_Recorder_1_read_Read_CombinedDataElement.WriteData
            OpServerCallDcm_MainFunction_ReadData_DataServices_Minimum_Software_Version_Read_Minimum_Software_Version: operation=DataServices_Minimum_Software_Version_Read_Minimum_Software_Version.ReadData
            OpServerCallDcm_MainFunction_ReadDataLength_DataServices_Minimum_Software_Version_Read_Minimum_Software_Version: operation=DataServices_Minimum_Software_Version_Read_Minimum_Software_Version.ReadDataLength
            OpServerCallDcm_MainFunction_ConditionCheckRead_DataServices_Minimum_Software_Version_Read_Minimum_Software_Version: operation=DataServices_Minimum_Software_Version_Read_Minimum_Software_Version.ConditionCheckRead
            OpServerCallDcm_MainFunction_ReadData_DataServices_VINDataIdentifier_Read_VINDataIdentifier: operation=DataServices_VINDataIdentifier_Read_VINDataIdentifier.ReadData
            OpServerCallDcm_MainFunction_ConditionCheckRead_DataServices_VINDataIdentifier_Read_VINDataIdentifier: operation=DataServices_VINDataIdentifier_Read_VINDataIdentifier.ConditionCheckRead
            OpServerCallDcm_MainFunction_WriteData_DataServices_VINDataIdentifier_Read_VINDataIdentifier: operation=DataServices_VINDataIdentifier_Read_VINDataIdentifier.WriteData
            OpServerCallDcm_MainFunction_ReadData_DataServices_Diagnostic_User_Role_Read_Cebas_UserRole: operation=DataServices_Diagnostic_User_Role_Read_Cebas_UserRole.ReadData
            OpServerCallDcm_MainFunction_ConditionCheckRead_DataServices_Diagnostic_User_Role_Read_Cebas_UserRole: operation=DataServices_Diagnostic_User_Role_Read_Cebas_UserRole.ConditionCheckRead
            OpServerCallDcm_MainFunction_ReadData_DataServices_Secured_System_Date_and_Time_Read_GeneralizedTime: operation=DataServices_Secured_System_Date_and_Time_Read_GeneralizedTime.ReadData
            OpServerCallDcm_MainFunction_ConditionCheckRead_DataServices_Secured_System_Date_and_Time_Read_GeneralizedTime: operation=DataServices_Secured_System_Date_and_Time_Read_GeneralizedTime.ConditionCheckRead
            OpServerCallDcm_MainFunction_ReadData_DataServices_BootSoftwareVersion_Read_Boot_SW_year: operation=DataServices_BootSoftwareVersion_Read_Boot_SW_year.ReadData
            OpServerCallDcm_MainFunction_ConditionCheckRead_DataServices_BootSoftwareVersion_Read_Boot_SW_year: operation=DataServices_BootSoftwareVersion_Read_Boot_SW_year.ConditionCheckRead
            OpServerCallDcm_MainFunction_ReadData_DataServices_BootSoftwareVersion_Read_Boot_SW_patch_level: operation=DataServices_BootSoftwareVersion_Read_Boot_SW_patch_level.ReadData
            OpServerCallDcm_MainFunction_ConditionCheckRead_DataServices_BootSoftwareVersion_Read_Boot_SW_patch_level: operation=DataServices_BootSoftwareVersion_Read_Boot_SW_patch_level.ConditionCheckRead
            OpServerCallDcm_MainFunction_ReadData_DataServices_BootSoftwareVersion_Read_Boot_SW_week: operation=DataServices_BootSoftwareVersion_Read_Boot_SW_week.ReadData
            OpServerCallDcm_MainFunction_ConditionCheckRead_DataServices_BootSoftwareVersion_Read_Boot_SW_week: operation=DataServices_BootSoftwareVersion_Read_Boot_SW_week.ConditionCheckRead
            OpServerCallDcm_MainFunction_ReadData_DataServices_Reprogramming_Attempt_Counter_Read_Reprogramming_Attempts: operation=DataServices_Reprogramming_Attempt_Counter_Read_Reprogramming_Attempts.ReadData
            OpServerCallDcm_MainFunction_ReadDataLength_DataServices_Reprogramming_Attempt_Counter_Read_Reprogramming_Attempts: operation=DataServices_Reprogramming_Attempt_Counter_Read_Reprogramming_Attempts.ReadDataLength
            OpServerCallDcm_MainFunction_ConditionCheckRead_DataServices_Reprogramming_Attempt_Counter_Read_Reprogramming_Attempts: operation=DataServices_Reprogramming_Attempt_Counter_Read_Reprogramming_Attempts.ConditionCheckRead
            OpServerCallDcm_MainFunction_ReadData_DataServices_Standard_Application_SW_Package_Information_Read_Standard_Applicatio_5346fb60: operation=DataServices_Standard_Application_SW_Package_Information_Read_Standard_Application_SW_Package_Major_Version.ReadData
            OpServerCallDcm_MainFunction_ConditionCheckRead_DataServices_Standard_Application_SW_Package_Information_Read_Standard_d1ff0da8: operation=DataServices_Standard_Application_SW_Package_Information_Read_Standard_Application_SW_Package_Major_Version.ConditionCheckRead
            OpServerCallDcm_MainFunction_ReadData_DataServices_Standard_Application_SW_Package_Information_Read_Standard_Applicatio_d6bd0910: operation=DataServices_Standard_Application_SW_Package_Information_Read_Standard_Application_SW_Package_Patch_Level.ReadData
            OpServerCallDcm_MainFunction_ConditionCheckRead_DataServices_Standard_Application_SW_Package_Information_Read_Standard_df5d7b2b: operation=DataServices_Standard_Application_SW_Package_Information_Read_Standard_Application_SW_Package_Patch_Level.ConditionCheckRead
            OpServerCallDcm_MainFunction_ReadData_DataServices_Standard_Application_SW_Package_Information_Read_Standard_Applicatio_e593fe1c: operation=DataServices_Standard_Application_SW_Package_Information_Read_Standard_Application_SW_Package_Minor_Version.ReadData
            OpServerCallDcm_MainFunction_ConditionCheckRead_DataServices_Standard_Application_SW_Package_Information_Read_Standard_672a08d4: operation=DataServices_Standard_Application_SW_Package_Information_Read_Standard_Application_SW_Package_Minor_Version.ConditionCheckRead
            OpServerCallDcm_MainFunction_ReadData_DataServices_Standard_Application_SW_Package_Information_Read_Supplier_Identification: operation=DataServices_Standard_Application_SW_Package_Information_Read_Supplier_Identification.ReadData
            OpServerCallDcm_MainFunction_ConditionCheckRead_DataServices_Standard_Application_SW_Package_Information_Read_Supplier_604e1381: operation=DataServices_Standard_Application_SW_Package_Information_Read_Supplier_Identification.ConditionCheckRead
            OpServerCallDcm_MainFunction_ReadData_DataServices_Standard_Application_SW_Package_Information_Read_Standard_Applicatio_d6271e2f: operation=DataServices_Standard_Application_SW_Package_Information_Read_Standard_Application_SW_Package_Build_Version.ReadData
            OpServerCallDcm_MainFunction_ConditionCheckRead_DataServices_Standard_Application_SW_Package_Information_Read_Standard_549ee8e7: operation=DataServices_Standard_Application_SW_Package_Information_Read_Standard_Application_SW_Package_Build_Version.ConditionCheckRead
            OpServerCallDcm_MainFunction_ReadData_DataServices_Dump_of_Vedoc_Relevant_Information_Read_PatchedObject: operation=DataServices_Dump_of_Vedoc_Relevant_Information_Read_PatchedObject.ReadData
            OpServerCallDcm_MainFunction_ReadDataLength_DataServices_Dump_of_Vedoc_Relevant_Information_Read_PatchedObject: operation=DataServices_Dump_of_Vedoc_Relevant_Information_Read_PatchedObject.ReadDataLength
            OpServerCallDcm_MainFunction_ConditionCheckRead_DataServices_Dump_of_Vedoc_Relevant_Information_Read_PatchedObject: operation=DataServices_Dump_of_Vedoc_Relevant_Information_Read_PatchedObject.ConditionCheckRead
            OpServerCallDcm_MainFunction_ReadData_DataServices_ECU_Name_Read_Diagnostic_ECU_Name: operation=DataServices_ECU_Name_Read_Diagnostic_ECU_Name.ReadData
            OpServerCallDcm_MainFunction_ReadDataLength_DataServices_ECU_Name_Read_Diagnostic_ECU_Name: operation=DataServices_ECU_Name_Read_Diagnostic_ECU_Name.ReadDataLength
            OpServerCallDcm_MainFunction_ConditionCheckRead_DataServices_ECU_Name_Read_Diagnostic_ECU_Name: operation=DataServices_ECU_Name_Read_Diagnostic_ECU_Name.ConditionCheckRead
            OpServerCallDcm_MainFunction_ReadData_DataServices_Security_Event_Log_Read_Security_Event_Log: operation=DataServices_Security_Event_Log_Read_Security_Event_Log.ReadData
            OpServerCallDcm_MainFunction_ReadDataLength_DataServices_Security_Event_Log_Read_Security_Event_Log: operation=DataServices_Security_Event_Log_Read_Security_Event_Log.ReadDataLength
            OpServerCallDcm_MainFunction_ConditionCheckRead_DataServices_Security_Event_Log_Read_Security_Event_Log: operation=DataServices_Security_Event_Log_Read_Security_Event_Log.ConditionCheckRead
            OpServerCallDcm_MainFunction_ReadData_DataServices_Adjust_ISO_15765_2_Block_Size_and_STmin_Parameter_Read_STmin_Value_a_875d818d: operation=DataServices_Adjust_ISO_15765_2_Block_Size_and_STmin_Parameter_Read_STmin_Value_as_defined_in_ISO_15765_2.ReadData
            OpServerCallDcm_MainFunction_ConditionCheckRead_DataServices_Adjust_ISO_15765_2_Block_Size_and_STmin_Parameter_Read_STm_8ebdf3b6: operation=DataServices_Adjust_ISO_15765_2_Block_Size_and_STmin_Parameter_Read_STmin_Value_as_defined_in_ISO_15765_2.ConditionCheckRead
            OpServerCallDcm_MainFunction_WriteData_DataServices_Adjust_ISO_15765_2_Block_Size_and_STmin_Parameter_Read_STmin_Value_4cd390ee: operation=DataServices_Adjust_ISO_15765_2_Block_Size_and_STmin_Parameter_Read_STmin_Value_as_defined_in_ISO_15765_2.WriteData
            OpServerCallDcm_MainFunction_ReadData_DataServices_Adjust_ISO_15765_2_Block_Size_and_STmin_Parameter_Read_Block_Size_Va_7183c982: operation=DataServices_Adjust_ISO_15765_2_Block_Size_and_STmin_Parameter_Read_Block_Size_Value_as_defined_in_ISO_15765_2.ReadData
            OpServerCallDcm_MainFunction_ConditionCheckRead_DataServices_Adjust_ISO_15765_2_Block_Size_and_STmin_Parameter_Read_Blo_1e6443eb: operation=DataServices_Adjust_ISO_15765_2_Block_Size_and_STmin_Parameter_Read_Block_Size_Value_as_defined_in_ISO_15765_2.ConditionCheckRead
            OpServerCallDcm_MainFunction_WriteData_DataServices_Adjust_ISO_15765_2_Block_Size_and_STmin_Parameter_Read_Block_Size_V_8411ccea: operation=DataServices_Adjust_ISO_15765_2_Block_Size_and_STmin_Parameter_Read_Block_Size_Value_as_defined_in_ISO_15765_2.WriteData
            OpServerCallDcm_MainFunction_ReadData_DataServices_SSA_Version_Information_Read_SSA_Patch_Level: operation=DataServices_SSA_Version_Information_Read_SSA_Patch_Level.ReadData
            OpServerCallDcm_MainFunction_ConditionCheckRead_DataServices_SSA_Version_Information_Read_SSA_Patch_Level: operation=DataServices_SSA_Version_Information_Read_SSA_Patch_Level.ConditionCheckRead
            OpServerCallDcm_MainFunction_ReadData_DataServices_SSA_Version_Information_Read_SSA_Major_Version: operation=DataServices_SSA_Version_Information_Read_SSA_Major_Version.ReadData
            OpServerCallDcm_MainFunction_ConditionCheckRead_DataServices_SSA_Version_Information_Read_SSA_Major_Version: operation=DataServices_SSA_Version_Information_Read_SSA_Major_Version.ConditionCheckRead
            OpServerCallDcm_MainFunction_ReadData_DataServices_SSA_Version_Information_Read_SSA_Minor_Version: operation=DataServices_SSA_Version_Information_Read_SSA_Minor_Version.ReadData
            OpServerCallDcm_MainFunction_ConditionCheckRead_DataServices_SSA_Version_Information_Read_SSA_Minor_Version: operation=DataServices_SSA_Version_Information_Read_SSA_Minor_Version.ConditionCheckRead
            OpServerCallDcm_MainFunction_ReadData_DataServices_SoftwareSupplier_Read_Software_Logical_Block_Supplier_Identification: operation=DataServices_SoftwareSupplier_Read_Software_Logical_Block_Supplier_Identification.ReadData
            OpServerCallDcm_MainFunction_ReadDataLength_DataServices_SoftwareSupplier_Read_Software_Logical_Block_Supplier_Identification: operation=DataServices_SoftwareSupplier_Read_Software_Logical_Block_Supplier_Identification.ReadDataLength
            OpServerCallDcm_MainFunction_ConditionCheckRead_DataServices_SoftwareSupplier_Read_Software_Logical_Block_Supplier_Iden_bbc01b7a: operation=DataServices_SoftwareSupplier_Read_Software_Logical_Block_Supplier_Identification.ConditionCheckRead
            OpServerCallDcm_MainFunction_ReadData_DataServices_DDS_Package_Release_Read_DDS_Package_Release_of_Boot_Software_Month_Boot: operation=DataServices_DDS_Package_Release_Read_DDS_Package_Release_of_Boot_Software_Month_Boot.ReadData
            OpServerCallDcm_MainFunction_ConditionCheckRead_DataServices_DDS_Package_Release_Read_DDS_Package_Release_of_Boot_Softw_93bc8fc0: operation=DataServices_DDS_Package_Release_Read_DDS_Package_Release_of_Boot_Software_Month_Boot.ConditionCheckRead
            OpServerCallDcm_MainFunction_ReadData_DataServices_DDS_Package_Release_Read_DDS_Package_Release_of_Application_Software_508ee854: operation=DataServices_DDS_Package_Release_Read_DDS_Package_Release_of_Application_Software_Year_Appl.ReadData
            OpServerCallDcm_MainFunction_ConditionCheckRead_DataServices_DDS_Package_Release_Read_DDS_Package_Release_of_Applicatio_1ab77fbe: operation=DataServices_DDS_Package_Release_Read_DDS_Package_Release_of_Application_Software_Year_Appl.ConditionCheckRead
            OpServerCallDcm_MainFunction_ReadData_DataServices_DDS_Package_Release_Read_DDS_Package_Release_of_Application_Software_9384890e: operation=DataServices_DDS_Package_Release_Read_DDS_Package_Release_of_Application_Software_Month_Appl.ReadData
            OpServerCallDcm_MainFunction_ConditionCheckRead_DataServices_DDS_Package_Release_Read_DDS_Package_Release_of_Applicatio_d311bbff: operation=DataServices_DDS_Package_Release_Read_DDS_Package_Release_of_Application_Software_Month_Appl.ConditionCheckRead
            OpServerCallDcm_MainFunction_ReadData_DataServices_DDS_Package_Release_Read_DDS_Package_Release_of_Boot_Software_Year_Boot: operation=DataServices_DDS_Package_Release_Read_DDS_Package_Release_of_Boot_Software_Year_Boot.ReadData
            OpServerCallDcm_MainFunction_ConditionCheckRead_DataServices_DDS_Package_Release_Read_DDS_Package_Release_of_Boot_Softw_f1654615: operation=DataServices_DDS_Package_Release_Read_DDS_Package_Release_of_Boot_Software_Year_Boot.ConditionCheckRead
            OpServerCallDcm_MainFunction_ReadData_DataServices_Security_Event_Log_Current_Counter_Values_Read_Security_Event_Log_Cu_144ec053: operation=DataServices_Security_Event_Log_Current_Counter_Values_Read_Security_Event_Log_Current_Counter_Values.ReadData
            OpServerCallDcm_MainFunction_ReadDataLength_DataServices_Security_Event_Log_Current_Counter_Values_Read_Security_Event_02f41c9e: operation=DataServices_Security_Event_Log_Current_Counter_Values_Read_Security_Event_Log_Current_Counter_Values.ReadDataLength
            OpServerCallDcm_MainFunction_ConditionCheckRead_DataServices_Security_Event_Log_Current_Counter_Values_Read_Security_Ev_e083107d: operation=DataServices_Security_Event_Log_Current_Counter_Values_Read_Security_Event_Log_Current_Counter_Values.ConditionCheckRead
            OpServerCallDcm_MainFunction_ReadData_DataServices_Supported_configuration_mechanisms_Read_Config_mechanisms: operation=DataServices_Supported_configuration_mechanisms_Read_Config_mechanisms.ReadData
            OpServerCallDcm_MainFunction_ConditionCheckRead_DataServices_Supported_configuration_mechanisms_Read_Config_mechanisms: operation=DataServices_Supported_configuration_mechanisms_Read_Config_mechanisms.ConditionCheckRead
            OpServerCallDcm_MainFunction_ReadData_DataServices_CAN_input_Read_Neues_Bitfeld_6: operation=DataServices_CAN_input_Read_Neues_Bitfeld_6.ReadData
            OpServerCallDcm_MainFunction_ConditionCheckRead_DataServices_CAN_input_Read_Neues_Bitfeld_6: operation=DataServices_CAN_input_Read_Neues_Bitfeld_6.ConditionCheckRead
            OpServerCallDcm_MainFunction_ReadData_DataServices_CAN_input_Read_Neues_Bitfeld_5: operation=DataServices_CAN_input_Read_Neues_Bitfeld_5.ReadData
            OpServerCallDcm_MainFunction_ConditionCheckRead_DataServices_CAN_input_Read_Neues_Bitfeld_5: operation=DataServices_CAN_input_Read_Neues_Bitfeld_5.ConditionCheckRead
            OpServerCallDcm_MainFunction_ReadData_DataServices_CAN_input_Read_Neues_Bitfeld_4: operation=DataServices_CAN_input_Read_Neues_Bitfeld_4.ReadData
            OpServerCallDcm_MainFunction_ConditionCheckRead_DataServices_CAN_input_Read_Neues_Bitfeld_4: operation=DataServices_CAN_input_Read_Neues_Bitfeld_4.ConditionCheckRead
            OpServerCallDcm_MainFunction_ReadData_DataServices_CAN_input_Read_Neues_Bitfeld_3: operation=DataServices_CAN_input_Read_Neues_Bitfeld_3.ReadData
            OpServerCallDcm_MainFunction_ConditionCheckRead_DataServices_CAN_input_Read_Neues_Bitfeld_3: operation=DataServices_CAN_input_Read_Neues_Bitfeld_3.ConditionCheckRead
            OpServerCallDcm_MainFunction_ReadData_DataServices_CAN_input_Read_Supply_battery_voltage: operation=DataServices_CAN_input_Read_Supply_battery_voltage.ReadData
            OpServerCallDcm_MainFunction_ConditionCheckRead_DataServices_CAN_input_Read_Supply_battery_voltage: operation=DataServices_CAN_input_Read_Supply_battery_voltage.ConditionCheckRead
            OpServerCallDcm_MainFunction_ReadData_DataServices_CAN_input_Read_Neues_Bitfeld_2: operation=DataServices_CAN_input_Read_Neues_Bitfeld_2.ReadData
            OpServerCallDcm_MainFunction_ConditionCheckRead_DataServices_CAN_input_Read_Neues_Bitfeld_2: operation=DataServices_CAN_input_Read_Neues_Bitfeld_2.ConditionCheckRead
            OpServerCallDcm_MainFunction_ReadData_DataServices_CAN_input_Read_Neues_Bitfeld_1: operation=DataServices_CAN_input_Read_Neues_Bitfeld_1.ReadData
            OpServerCallDcm_MainFunction_ConditionCheckRead_DataServices_CAN_input_Read_Neues_Bitfeld_1: operation=DataServices_CAN_input_Read_Neues_Bitfeld_1.ConditionCheckRead
            OpServerCallDcm_MainFunction_ReadData_DataServices_SecOC_Vehicle_Shared_Secret_Hash_Read_SecOC_Vehicle_Shared_Secret_Hash: operation=DataServices_SecOC_Vehicle_Shared_Secret_Hash_Read_SecOC_Vehicle_Shared_Secret_Hash.ReadData
            OpServerCallDcm_MainFunction_ConditionCheckRead_DataServices_SecOC_Vehicle_Shared_Secret_Hash_Read_SecOC_Vehicle_Shared_fd4e32a3: operation=DataServices_SecOC_Vehicle_Shared_Secret_Hash_Read_SecOC_Vehicle_Shared_Secret_Hash.ConditionCheckRead
            OpServerCallDcm_MainFunction_ReadData_DataServices_Trust_model_ECU_CSR_Read_Trust_model_ECU_CSR: operation=DataServices_Trust_model_ECU_CSR_Read_Trust_model_ECU_CSR.ReadData
            OpServerCallDcm_MainFunction_ReadDataLength_DataServices_Trust_model_ECU_CSR_Read_Trust_model_ECU_CSR: operation=DataServices_Trust_model_ECU_CSR_Read_Trust_model_ECU_CSR.ReadDataLength
            OpServerCallDcm_MainFunction_ConditionCheckRead_DataServices_Trust_model_ECU_CSR_Read_Trust_model_ECU_CSR: operation=DataServices_Trust_model_ECU_CSR_Read_Trust_model_ECU_CSR.ConditionCheckRead
            OpServerCallDcm_MainFunction_ReadData_DataServices_Root_CA_Certificate_Read_Root_CA_Certificate: operation=DataServices_Root_CA_Certificate_Read_Root_CA_Certificate.ReadData
            OpServerCallDcm_MainFunction_ReadDataLength_DataServices_Root_CA_Certificate_Read_Root_CA_Certificate: operation=DataServices_Root_CA_Certificate_Read_Root_CA_Certificate.ReadDataLength
            OpServerCallDcm_MainFunction_ConditionCheckRead_DataServices_Root_CA_Certificate_Read_Root_CA_Certificate: operation=DataServices_Root_CA_Certificate_Read_Root_CA_Certificate.ConditionCheckRead
            OpServerCallDcm_MainFunction_ReadData_DataServices_ECUSerialNumberDataIdentifier_Read_ECU_Serial_Number: operation=DataServices_ECUSerialNumberDataIdentifier_Read_ECU_Serial_Number.ReadData
            OpServerCallDcm_MainFunction_ReadDataLength_DataServices_ECUSerialNumberDataIdentifier_Read_ECU_Serial_Number: operation=DataServices_ECUSerialNumberDataIdentifier_Read_ECU_Serial_Number.ReadDataLength
            OpServerCallDcm_MainFunction_ConditionCheckRead_DataServices_ECUSerialNumberDataIdentifier_Read_ECU_Serial_Number: operation=DataServices_ECUSerialNumberDataIdentifier_Read_ECU_Serial_Number.ConditionCheckRead
            OpServerCallDcm_MainFunction_ReadData_DataServices_VIN_Status_Read_VIN_Lock_Status: operation=DataServices_VIN_Status_Read_VIN_Lock_Status.ReadData
            OpServerCallDcm_MainFunction_ConditionCheckRead_DataServices_VIN_Status_Read_VIN_Lock_Status: operation=DataServices_VIN_Status_Read_VIN_Lock_Status.ConditionCheckRead
            OpServerCallDcm_MainFunction_ReadData_DataServices_VIN_Status_Read_VIN_Status: operation=DataServices_VIN_Status_Read_VIN_Status.ReadData
            OpServerCallDcm_MainFunction_ConditionCheckRead_DataServices_VIN_Status_Read_VIN_Status: operation=DataServices_VIN_Status_Read_VIN_Status.ConditionCheckRead
            OpServerCallDcm_MainFunction_ReadData_DataServices_Status_SSA_Pre_Compile_Switches_Read_Precompile_switch: operation=DataServices_Status_SSA_Pre_Compile_Switches_Read_Precompile_switch.ReadData
            OpServerCallDcm_MainFunction_ConditionCheckRead_DataServices_Status_SSA_Pre_Compile_Switches_Read_Precompile_switch: operation=DataServices_Status_SSA_Pre_Compile_Switches_Read_Precompile_switch.ConditionCheckRead
            OpServerCallDcm_MainFunction_ReadData_DataServices_PRE_SAFE_Recorder_2_read_Read_CombinedDataElement: operation=DataServices_PRE_SAFE_Recorder_2_read_Read_CombinedDataElement.ReadData
            OpServerCallDcm_MainFunction_ReadDataLength_DataServices_PRE_SAFE_Recorder_2_read_Read_CombinedDataElement: operation=DataServices_PRE_SAFE_Recorder_2_read_Read_CombinedDataElement.ReadDataLength
            OpServerCallDcm_MainFunction_ConditionCheckRead_DataServices_PRE_SAFE_Recorder_2_read_Read_CombinedDataElement: operation=DataServices_PRE_SAFE_Recorder_2_read_Read_CombinedDataElement.ConditionCheckRead
            OpServerCallDcm_MainFunction_WriteData_DataServices_PRE_SAFE_Recorder_2_read_Read_CombinedDataElement: operation=DataServices_PRE_SAFE_Recorder_2_read_Read_CombinedDataElement.WriteData
            OpServerCallDcm_MainFunction_ReadData_DataServices_BSR_Counter_read_Read_BSR_Counter: operation=DataServices_BSR_Counter_read_Read_BSR_Counter.ReadData
            OpServerCallDcm_MainFunction_ConditionCheckRead_DataServices_BSR_Counter_read_Read_BSR_Counter: operation=DataServices_BSR_Counter_read_Read_BSR_Counter.ConditionCheckRead
            OpServerCallDcm_MainFunction_ReadData_DataServices_Vehicle_Odometer_in_Low_Resolution_Read_Vehicle_Odometer_in_Low_Resolution: operation=DataServices_Vehicle_Odometer_in_Low_Resolution_Read_Vehicle_Odometer_in_Low_Resolution.ReadData
            OpServerCallDcm_MainFunction_ConditionCheckRead_DataServices_Vehicle_Odometer_in_Low_Resolution_Read_Vehicle_Odometer_i_78e7bc77: operation=DataServices_Vehicle_Odometer_in_Low_Resolution_Read_Vehicle_Odometer_in_Low_Resolution.ConditionCheckRead
            OpServerCallDcm_MainFunction_ReadData_DataServices_HardwareSupplier_Read_Hardware_Supplier_Identification: operation=DataServices_HardwareSupplier_Read_Hardware_Supplier_Identification.ReadData
            OpServerCallDcm_MainFunction_ConditionCheckRead_DataServices_HardwareSupplier_Read_Hardware_Supplier_Identification: operation=DataServices_HardwareSupplier_Read_Hardware_Supplier_Identification.ConditionCheckRead
            OpServerCallDcm_MainFunction_ReadData_DataServices_MercedesCarGroupSoftware_Read_Software_Logical_Block_Numbers: operation=DataServices_MercedesCarGroupSoftware_Read_Software_Logical_Block_Numbers.ReadData
            OpServerCallDcm_MainFunction_ReadDataLength_DataServices_MercedesCarGroupSoftware_Read_Software_Logical_Block_Numbers: operation=DataServices_MercedesCarGroupSoftware_Read_Software_Logical_Block_Numbers.ReadDataLength
            OpServerCallDcm_MainFunction_ConditionCheckRead_DataServices_MercedesCarGroupSoftware_Read_Software_Logical_Block_Numbers: operation=DataServices_MercedesCarGroupSoftware_Read_Software_Logical_Block_Numbers.ConditionCheckRead
            OpServerCallDcm_MainFunction_ReadData_DataServices_SecOC_PDU_Data_IDs_and_Key_CMACs_Read_Secured_PDU_Data_IDs_and_Key_CMACs: operation=DataServices_SecOC_PDU_Data_IDs_and_Key_CMACs_Read_Secured_PDU_Data_IDs_and_Key_CMACs.ReadData
            OpServerCallDcm_MainFunction_ReadDataLength_DataServices_SecOC_PDU_Data_IDs_and_Key_CMACs_Read_Secured_PDU_Data_IDs_and_20f7a4c8: operation=DataServices_SecOC_PDU_Data_IDs_and_Key_CMACs_Read_Secured_PDU_Data_IDs_and_Key_CMACs.ReadDataLength
            OpServerCallDcm_MainFunction_ConditionCheckRead_DataServices_SecOC_PDU_Data_IDs_and_Key_CMACs_Read_Secured_PDU_Data_IDs_f1e2ca4a: operation=DataServices_SecOC_PDU_Data_IDs_and_Key_CMACs_Read_Secured_PDU_Data_IDs_and_Key_CMACs.ConditionCheckRead
            OpServerCallDcm_MainFunction_ReadData_DataServices_Current_Operating_Time_Read_Current_Operating_Time: operation=DataServices_Current_Operating_Time_Read_Current_Operating_Time.ReadData
            OpServerCallDcm_MainFunction_ConditionCheckRead_DataServices_Current_Operating_Time_Read_Current_Operating_Time: operation=DataServices_Current_Operating_Time_Read_Current_Operating_Time.ConditionCheckRead
            OpServerCallDcm_MainFunction_ReadData_DataServices_Current_Operating_Time_Read_Operating_Time_Status: operation=DataServices_Current_Operating_Time_Read_Operating_Time_Status.ReadData
            OpServerCallDcm_MainFunction_ConditionCheckRead_DataServices_Current_Operating_Time_Read_Operating_Time_Status: operation=DataServices_Current_Operating_Time_Read_Operating_Time_Status.ConditionCheckRead
            OpServerCallDcm_MainFunction_ReadData_DataServices_Trust_model_Root_CA_certificate_Read_Trust_model_Root_CA_certificate: operation=DataServices_Trust_model_Root_CA_certificate_Read_Trust_model_Root_CA_certificate.ReadData
            OpServerCallDcm_MainFunction_ReadDataLength_DataServices_Trust_model_Root_CA_certificate_Read_Trust_model_Root_CA_certificate: operation=DataServices_Trust_model_Root_CA_certificate_Read_Trust_model_Root_CA_certificate.ReadDataLength
            OpServerCallDcm_MainFunction_ConditionCheckRead_DataServices_Trust_model_Root_CA_certificate_Read_Trust_model_Root_CA_c_92b53846: operation=DataServices_Trust_model_Root_CA_certificate_Read_Trust_model_Root_CA_certificate.ConditionCheckRead
            OpServerCallDcm_MainFunction_ReadData_DataServices_RandomNumber_Read_Generated_Random_Number_Result: operation=DataServices_RandomNumber_Read_Generated_Random_Number_Result.ReadData
            OpServerCallDcm_MainFunction_ConditionCheckRead_DataServices_RandomNumber_Read_Generated_Random_Number_Result: operation=DataServices_RandomNumber_Read_Generated_Random_Number_Result.ConditionCheckRead
            OpServerCallDcm_MainFunction_ReadData_DataServices_RandomNumber_Read_Generated_Random_Number: operation=DataServices_RandomNumber_Read_Generated_Random_Number.ReadData
            OpServerCallDcm_MainFunction_ConditionCheckRead_DataServices_RandomNumber_Read_Generated_Random_Number: operation=DataServices_RandomNumber_Read_Generated_Random_Number.ConditionCheckRead
            OpServerCallDcm_MainFunction_ReadData_DataServices_MercedesCarGroupHardware_Read_Hardware_Part_Number: operation=DataServices_MercedesCarGroupHardware_Read_Hardware_Part_Number.ReadData
            OpServerCallDcm_MainFunction_ConditionCheckRead_DataServices_MercedesCarGroupHardware_Read_Hardware_Part_Number: operation=DataServices_MercedesCarGroupHardware_Read_Hardware_Part_Number.ConditionCheckRead
            OpServerCallDcm_MainFunction_ReadData_DataServices_Internal_ECU_information_Read_ECU_Temperature: operation=DataServices_Internal_ECU_information_Read_ECU_Temperature.ReadData
            OpServerCallDcm_MainFunction_ConditionCheckRead_DataServices_Internal_ECU_information_Read_ECU_Temperature: operation=DataServices_Internal_ECU_information_Read_ECU_Temperature.ConditionCheckRead
            OpServerCallDcm_MainFunction_ReadData_DataServices_Internal_ECU_information_Read_MOTOR_Current: operation=DataServices_Internal_ECU_information_Read_MOTOR_Current.ReadData
            OpServerCallDcm_MainFunction_ConditionCheckRead_DataServices_Internal_ECU_information_Read_MOTOR_Current: operation=DataServices_Internal_ECU_information_Read_MOTOR_Current.ConditionCheckRead
            OpServerCallDcm_MainFunction_ReadData_DataServices_Internal_ECU_information_Read_Autosar_System_State_EcuM_State: operation=DataServices_Internal_ECU_information_Read_Autosar_System_State_EcuM_State.ReadData
            OpServerCallDcm_MainFunction_ConditionCheckRead_DataServices_Internal_ECU_information_Read_Autosar_System_State_EcuM_State: operation=DataServices_Internal_ECU_information_Read_Autosar_System_State_EcuM_State.ConditionCheckRead
            OpServerCallDcm_MainFunction_ReadData_DataServices_Backend_CA_Certificate_Read_Backend_CA_Certificate: operation=DataServices_Backend_CA_Certificate_Read_Backend_CA_Certificate.ReadData
            OpServerCallDcm_MainFunction_ReadDataLength_DataServices_Backend_CA_Certificate_Read_Backend_CA_Certificate: operation=DataServices_Backend_CA_Certificate_Read_Backend_CA_Certificate.ReadDataLength
            OpServerCallDcm_MainFunction_ConditionCheckRead_DataServices_Backend_CA_Certificate_Read_Backend_CA_Certificate: operation=DataServices_Backend_CA_Certificate_Read_Backend_CA_Certificate.ConditionCheckRead
            OpServerCallDcm_MainFunction_ReadData_DataServices_Trust_model_Intermediate_CA_certificate_Read_Trust_model_Intermediat_efc0bf7d: operation=DataServices_Trust_model_Intermediate_CA_certificate_Read_Trust_model_Intermediate_CA_Certificate.ReadData
            OpServerCallDcm_MainFunction_ReadDataLength_DataServices_Trust_model_Intermediate_CA_certificate_Read_Trust_model_Inter_87b29033: operation=DataServices_Trust_model_Intermediate_CA_certificate_Read_Trust_model_Intermediate_CA_Certificate.ReadDataLength
            OpServerCallDcm_MainFunction_ConditionCheckRead_DataServices_Trust_model_Intermediate_CA_certificate_Read_Trust_model_I_cb17c3a4: operation=DataServices_Trust_model_Intermediate_CA_certificate_Read_Trust_model_Intermediate_CA_Certificate.ConditionCheckRead
            OpServerCallDcm_MainFunction_ReadData_DataServices_Diagnostic_Authentication_Certificate_Identification_Read_Diagnostic_479ed098: operation=DataServices_Diagnostic_Authentication_Certificate_Identification_Read_Diagnostic_Authentication_Certificate_Serial_Number.ReadData
            OpServerCallDcm_MainFunction_ReadDataLength_DataServices_Diagnostic_Authentication_Certificate_Identification_Read_Diag_b6f996ca: operation=DataServices_Diagnostic_Authentication_Certificate_Identification_Read_Diagnostic_Authentication_Certificate_Serial_Number.ReadDataLength
            OpServerCallDcm_MainFunction_ConditionCheckRead_DataServices_Diagnostic_Authentication_Certificate_Identification_Read_31cfb367: operation=DataServices_Diagnostic_Authentication_Certificate_Identification_Read_Diagnostic_Authentication_Certificate_Serial_Number.ConditionCheckRead
            OpServerCallDcm_MainFunction_ReadData_DataServices_Diagnostic_Authentication_Certificate_Identification_Read_Diagnostic_7b6e3e81: operation=DataServices_Diagnostic_Authentication_Certificate_Identification_Read_Diagnostic_Authentication_Certificate_Issuer.ReadData
            OpServerCallDcm_MainFunction_ConditionCheckRead_DataServices_Diagnostic_Authentication_Certificate_Identification_Read_2360ccaf: operation=DataServices_Diagnostic_Authentication_Certificate_Identification_Read_Diagnostic_Authentication_Certificate_Issuer.ConditionCheckRead
            OpServerCallDcm_MainFunction_ReadData_DataServices_SecOC_PDU_Data_IDs_and_Key_Checksum_Read_Secured_PDU_Data_IDs_and_Ke_5a872417: operation=DataServices_SecOC_PDU_Data_IDs_and_Key_Checksum_Read_Secured_PDU_Data_IDs_and_Key_Checksum.ReadData
            OpServerCallDcm_MainFunction_ReadDataLength_DataServices_SecOC_PDU_Data_IDs_and_Key_Checksum_Read_Secured_PDU_Data_IDs_8e4837a8: operation=DataServices_SecOC_PDU_Data_IDs_and_Key_Checksum_Read_Secured_PDU_Data_IDs_and_Key_Checksum.ReadDataLength
            OpServerCallDcm_MainFunction_ConditionCheckRead_DataServices_SecOC_PDU_Data_IDs_and_Key_Checksum_Read_Secured_PDU_Data_10beb3fd: operation=DataServices_SecOC_PDU_Data_IDs_and_Key_Checksum_Read_Secured_PDU_Data_IDs_and_Key_Checksum.ConditionCheckRead
            OpServerCallDcm_MainFunction_ReadData_DataServices_System_Time_read_Read_System_time: operation=DataServices_System_Time_read_Read_System_time.ReadData
            OpServerCallDcm_MainFunction_ConditionCheckRead_DataServices_System_Time_read_Read_System_time: operation=DataServices_System_Time_read_Read_System_time.ConditionCheckRead
            OpServerCallDcm_MainFunction_ReadData_DataServices_Trust_Model_Request_ephemeral_public_key_Read_Data_Signature: operation=DataServices_Trust_Model_Request_ephemeral_public_key_Read_Data_Signature.ReadData
            OpServerCallDcm_MainFunction_ConditionCheckRead_DataServices_Trust_Model_Request_ephemeral_public_key_Read_Data_Signature: operation=DataServices_Trust_Model_Request_ephemeral_public_key_Read_Data_Signature.ConditionCheckRead
            OpServerCallDcm_MainFunction_ReadData_DataServices_Trust_Model_Request_ephemeral_public_key_Read_Ephemeral_ECU_Public_Key: operation=DataServices_Trust_Model_Request_ephemeral_public_key_Read_Ephemeral_ECU_Public_Key.ReadData
            OpServerCallDcm_MainFunction_ConditionCheckRead_DataServices_Trust_Model_Request_ephemeral_public_key_Read_Ephemeral_EC_c383bd2e: operation=DataServices_Trust_Model_Request_ephemeral_public_key_Read_Ephemeral_ECU_Public_Key.ConditionCheckRead
            OpServerCallDcm_MainFunction_ReadData_DataServices_Trust_Model_Request_ephemeral_public_key_Read_Certificates: operation=DataServices_Trust_Model_Request_ephemeral_public_key_Read_Certificates.ReadData
            OpServerCallDcm_MainFunction_ReadDataLength_DataServices_Trust_Model_Request_ephemeral_public_key_Read_Certificates: operation=DataServices_Trust_Model_Request_ephemeral_public_key_Read_Certificates.ReadDataLength
            OpServerCallDcm_MainFunction_ConditionCheckRead_DataServices_Trust_Model_Request_ephemeral_public_key_Read_Certificates: operation=DataServices_Trust_Model_Request_ephemeral_public_key_Read_Certificates.ConditionCheckRead
            OpServerCallDcm_MainFunction_ReadData_DataServices_Trust_Model_Request_ephemeral_public_key_Read_Nonce: operation=DataServices_Trust_Model_Request_ephemeral_public_key_Read_Nonce.ReadData
            OpServerCallDcm_MainFunction_ConditionCheckRead_DataServices_Trust_Model_Request_ephemeral_public_key_Read_Nonce: operation=DataServices_Trust_Model_Request_ephemeral_public_key_Read_Nonce.ConditionCheckRead
            OpServerCallDcm_MainFunction_ReadData_DataServices_HW_input_Read_Voltage_KL30t: operation=DataServices_HW_input_Read_Voltage_KL30t.ReadData
            OpServerCallDcm_MainFunction_ConditionCheckRead_DataServices_HW_input_Read_Voltage_KL30t: operation=DataServices_HW_input_Read_Voltage_KL30t.ConditionCheckRead
            OpServerCallDcm_MainFunction_ReadData_DataServices_HW_input_Read_Voltage_Motor: operation=DataServices_HW_input_Read_Voltage_Motor.ReadData
            OpServerCallDcm_MainFunction_ConditionCheckRead_DataServices_HW_input_Read_Voltage_Motor: operation=DataServices_HW_input_Read_Voltage_Motor.ConditionCheckRead
            OpServerCallDcm_MainFunction_ReadData_DataServices_Diagnostic_Trace_Memory_Read_Diagnostic_Trace_Memory: operation=DataServices_Diagnostic_Trace_Memory_Read_Diagnostic_Trace_Memory.ReadData
            OpServerCallDcm_MainFunction_ConditionCheckRead_DataServices_Diagnostic_Trace_Memory_Read_Diagnostic_Trace_Memory: operation=DataServices_Diagnostic_Trace_Memory_Read_Diagnostic_Trace_Memory.ConditionCheckRead
            OpServerCallDcm_MainFunction_WriteData_DataServices_Diagnostic_Trace_Memory_Read_Diagnostic_Trace_Memory: operation=DataServices_Diagnostic_Trace_Memory_Read_Diagnostic_Trace_Memory.WriteData
            OpServerCallDcm_MainFunction_ReadData_DataServices_ReadFingerprint_Read_Software_Fingerprint_s: operation=DataServices_ReadFingerprint_Read_Software_Fingerprint_s.ReadData
            OpServerCallDcm_MainFunction_ReadDataLength_DataServices_ReadFingerprint_Read_Software_Fingerprint_s: operation=DataServices_ReadFingerprint_Read_Software_Fingerprint_s.ReadDataLength
            OpServerCallDcm_MainFunction_ConditionCheckRead_DataServices_ReadFingerprint_Read_Software_Fingerprint_s: operation=DataServices_ReadFingerprint_Read_Software_Fingerprint_s.ConditionCheckRead
            OpServerCallDcm_MainFunction_ReadData_DataServices_Trust_model_full_chain_of_trust_certificates_Read_Trust_model_certificates: operation=DataServices_Trust_model_full_chain_of_trust_certificates_Read_Trust_model_certificates.ReadData
            OpServerCallDcm_MainFunction_ReadDataLength_DataServices_Trust_model_full_chain_of_trust_certificates_Read_Trust_model_d58fd73d: operation=DataServices_Trust_model_full_chain_of_trust_certificates_Read_Trust_model_certificates.ReadDataLength
            OpServerCallDcm_MainFunction_ConditionCheckRead_DataServices_Trust_model_full_chain_of_trust_certificates_Read_Trust_mo_7630b0be: operation=DataServices_Trust_model_full_chain_of_trust_certificates_Read_Trust_model_certificates.ConditionCheckRead
            OpServerCallDcm_MainFunction_ReadData_DataServices_ZZZ_Vehicle_Equipment_Development_Read_Zykluszeit_Messtechnik: operation=DataServices_ZZZ_Vehicle_Equipment_Development_Read_Zykluszeit_Messtechnik.ReadData
            OpServerCallDcm_MainFunction_ConditionCheckRead_DataServices_ZZZ_Vehicle_Equipment_Development_Read_Zykluszeit_Messtechnik: operation=DataServices_ZZZ_Vehicle_Equipment_Development_Read_Zykluszeit_Messtechnik.ConditionCheckRead
            OpServerCallDcm_MainFunction_WriteData_DataServices_ZZZ_Vehicle_Equipment_Development_Read_Zykluszeit_Messtechnik: operation=DataServices_ZZZ_Vehicle_Equipment_Development_Read_Zykluszeit_Messtechnik.WriteData
            OpServerCallDcm_MainFunction_ReadData_DataServices_ZZZ_Vehicle_Equipment_Development_Read_Bitfield: operation=DataServices_ZZZ_Vehicle_Equipment_Development_Read_Bitfield.ReadData
            OpServerCallDcm_MainFunction_ConditionCheckRead_DataServices_ZZZ_Vehicle_Equipment_Development_Read_Bitfield: operation=DataServices_ZZZ_Vehicle_Equipment_Development_Read_Bitfield.ConditionCheckRead
            OpServerCallDcm_MainFunction_WriteData_DataServices_ZZZ_Vehicle_Equipment_Development_Read_Bitfield: operation=DataServices_ZZZ_Vehicle_Equipment_Development_Read_Bitfield.WriteData
            OpServerCallDcm_MainFunction_ReadData_DataServices_PRE_SAFE_Counter_read_Read_CombinedDataElement: operation=DataServices_PRE_SAFE_Counter_read_Read_CombinedDataElement.ReadData
            OpServerCallDcm_MainFunction_ReadDataLength_DataServices_PRE_SAFE_Counter_read_Read_CombinedDataElement: operation=DataServices_PRE_SAFE_Counter_read_Read_CombinedDataElement.ReadDataLength
            OpServerCallDcm_MainFunction_ConditionCheckRead_DataServices_PRE_SAFE_Counter_read_Read_CombinedDataElement: operation=DataServices_PRE_SAFE_Counter_read_Read_CombinedDataElement.ConditionCheckRead
            OpServerCallDcm_MainFunction_WriteData_DataServices_PRE_SAFE_Counter_read_Read_CombinedDataElement: operation=DataServices_PRE_SAFE_Counter_read_Read_CombinedDataElement.WriteData
            OpServerCallDcm_MainFunction_ReadData_DataServices_Trust_model_Backend_CA_certificate_Read_Trust_model_Backend_CA_certificate: operation=DataServices_Trust_model_Backend_CA_certificate_Read_Trust_model_Backend_CA_certificate.ReadData
            OpServerCallDcm_MainFunction_ReadDataLength_DataServices_Trust_model_Backend_CA_certificate_Read_Trust_model_Backend_CA_30235e1a: operation=DataServices_Trust_model_Backend_CA_certificate_Read_Trust_model_Backend_CA_certificate.ReadDataLength
            OpServerCallDcm_MainFunction_ConditionCheckRead_DataServices_Trust_model_Backend_CA_certificate_Read_Trust_model_Backen_939c3999: operation=DataServices_Trust_model_Backend_CA_certificate_Read_Trust_model_Backend_CA_certificate.ConditionCheckRead
            OpServerCallDcm_MainFunction_ReadData_DataServices_ActiveDiagnosticInformation_Read_Session: operation=DataServices_ActiveDiagnosticInformation_Read_Session.ReadData
            OpServerCallDcm_MainFunction_ConditionCheckRead_DataServices_ActiveDiagnosticInformation_Read_Session: operation=DataServices_ActiveDiagnosticInformation_Read_Session.ConditionCheckRead
            OpServerCallDcm_MainFunction_ReadData_DataServices_ActiveDiagnosticInformation_Read_Identification: operation=DataServices_ActiveDiagnosticInformation_Read_Identification.ReadData
            OpServerCallDcm_MainFunction_ConditionCheckRead_DataServices_ActiveDiagnosticInformation_Read_Identification: operation=DataServices_ActiveDiagnosticInformation_Read_Identification.ConditionCheckRead
            OpServerCallDcm_MainFunction_ReadData_DataServices_Real_Time_Offset_Read_TickCount: operation=DataServices_Real_Time_Offset_Read_TickCount.ReadData
            OpServerCallDcm_MainFunction_ConditionCheckRead_DataServices_Real_Time_Offset_Read_TickCount: operation=DataServices_Real_Time_Offset_Read_TickCount.ConditionCheckRead
            OpServerCallDcm_MainFunction_ReadData_DataServices_Real_Time_Offset_Read_Real_Time_Offset: operation=DataServices_Real_Time_Offset_Read_Real_Time_Offset.ReadData
            OpServerCallDcm_MainFunction_ConditionCheckRead_DataServices_Real_Time_Offset_Read_Real_Time_Offset: operation=DataServices_Real_Time_Offset_Read_Real_Time_Offset.ConditionCheckRead
            OpServerCallDcm_MainFunction_ReadData_DataServices_SoftwareVersion_Read_Software_Logical_Block_Version_Information: operation=DataServices_SoftwareVersion_Read_Software_Logical_Block_Version_Information.ReadData
            OpServerCallDcm_MainFunction_ReadDataLength_DataServices_SoftwareVersion_Read_Software_Logical_Block_Version_Information: operation=DataServices_SoftwareVersion_Read_Software_Logical_Block_Version_Information.ReadDataLength
            OpServerCallDcm_MainFunction_ConditionCheckRead_DataServices_SoftwareVersion_Read_Software_Logical_Block_Version_Information: operation=DataServices_SoftwareVersion_Read_Software_Logical_Block_Version_Information.ConditionCheckRead
            OpServerCallDcm_MainFunction_ReadData_DataServices_CAN_output_Read_CANoutput1: operation=DataServices_CAN_output_Read_CANoutput1.ReadData
            OpServerCallDcm_MainFunction_ConditionCheckRead_DataServices_CAN_output_Read_CANoutput1: operation=DataServices_CAN_output_Read_CANoutput1.ConditionCheckRead
            OpServerCallDcm_MainFunction_ReadData_DataServices_Access_Control_List_Version_Read_Basic_ACL_Version_Generation_Time_GTC: operation=DataServices_Access_Control_List_Version_Read_Basic_ACL_Version_Generation_Time_GTC.ReadData
            OpServerCallDcm_MainFunction_ConditionCheckRead_DataServices_Access_Control_List_Version_Read_Basic_ACL_Version_Generat_d4aa931c: operation=DataServices_Access_Control_List_Version_Read_Basic_ACL_Version_Generation_Time_GTC.ConditionCheckRead
            OpServerCallDcm_MainFunction_ReadData_DataServices_Access_Control_List_Version_Read_ECU_indvidual_ACL_Version_Generatio_7ab5b03e: operation=DataServices_Access_Control_List_Version_Read_ECU_indvidual_ACL_Version_Generation_Time_GTC.ReadData
            OpServerCallDcm_MainFunction_ConditionCheckRead_DataServices_Access_Control_List_Version_Read_ECU_indvidual_ACL_Version_308c27d4: operation=DataServices_Access_Control_List_Version_Read_ECU_indvidual_ACL_Version_Generation_Time_GTC.ConditionCheckRead
            OpServerCallDcm_MainFunction_ReadData_DataServices_Access_Control_List_Version_Read_Basic_ACL_Hash: operation=DataServices_Access_Control_List_Version_Read_Basic_ACL_Hash.ReadData
            OpServerCallDcm_MainFunction_ConditionCheckRead_DataServices_Access_Control_List_Version_Read_Basic_ACL_Hash: operation=DataServices_Access_Control_List_Version_Read_Basic_ACL_Hash.ConditionCheckRead
            OpServerCallDcm_MainFunction_ReadData_DataServices_Access_Control_List_Version_Read_Basic_ACL_Version_Candela_File_Version_Patch: operation=DataServices_Access_Control_List_Version_Read_Basic_ACL_Version_Candela_File_Version_Patch.ReadData
            OpServerCallDcm_MainFunction_ConditionCheckRead_DataServices_Access_Control_List_Version_Read_Basic_ACL_Version_Candela_7d636ccf: operation=DataServices_Access_Control_List_Version_Read_Basic_ACL_Version_Candela_File_Version_Patch.ConditionCheckRead
            OpServerCallDcm_MainFunction_ReadData_DataServices_Access_Control_List_Version_Read_ECU_indvidual_ACL_Version_Candela_F_eb7d5d87: operation=DataServices_Access_Control_List_Version_Read_ECU_indvidual_ACL_Version_Candela_File_Version_Patch.ReadData
            OpServerCallDcm_MainFunction_ConditionCheckRead_DataServices_Access_Control_List_Version_Read_ECU_indvidual_ACL_Version_1456e08b: operation=DataServices_Access_Control_List_Version_Read_ECU_indvidual_ACL_Version_Candela_File_Version_Patch.ConditionCheckRead
            OpServerCallDcm_MainFunction_ReadData_DataServices_Access_Control_List_Version_Read_ECU_indvidual_ACL_Hash: operation=DataServices_Access_Control_List_Version_Read_ECU_indvidual_ACL_Hash.ReadData
            OpServerCallDcm_MainFunction_ConditionCheckRead_DataServices_Access_Control_List_Version_Read_ECU_indvidual_ACL_Hash: operation=DataServices_Access_Control_List_Version_Read_ECU_indvidual_ACL_Hash.ConditionCheckRead
            OpServerCallDcm_MainFunction_ReadData_DataServices_Access_Control_List_Version_Read_ECU_indvidual_ACL_Version_Candela_F_f6dfb68b: operation=DataServices_Access_Control_List_Version_Read_ECU_indvidual_ACL_Version_Candela_File_Version_Minor.ReadData
            OpServerCallDcm_MainFunction_ConditionCheckRead_DataServices_Access_Control_List_Version_Read_ECU_indvidual_ACL_Version_09f40b87: operation=DataServices_Access_Control_List_Version_Read_ECU_indvidual_ACL_Version_Candela_File_Version_Minor.ConditionCheckRead
            OpServerCallDcm_MainFunction_ReadData_DataServices_Access_Control_List_Version_Read_ECU_indvidual_ACL_Version_Candela_F_346236b8: operation=DataServices_Access_Control_List_Version_Read_ECU_indvidual_ACL_Version_Candela_File_Version_Major.ReadData
            OpServerCallDcm_MainFunction_ConditionCheckRead_DataServices_Access_Control_List_Version_Read_ECU_indvidual_ACL_Version_cb498bb4: operation=DataServices_Access_Control_List_Version_Read_ECU_indvidual_ACL_Version_Candela_File_Version_Major.ConditionCheckRead
            OpServerCallDcm_MainFunction_ReadData_DataServices_Access_Control_List_Version_Read_Basic_ACL_Version_Candela_File_Version_Minor: operation=DataServices_Access_Control_List_Version_Read_Basic_ACL_Version_Candela_File_Version_Minor.ReadData
            OpServerCallDcm_MainFunction_ConditionCheckRead_DataServices_Access_Control_List_Version_Read_Basic_ACL_Version_Candela_60c187c3: operation=DataServices_Access_Control_List_Version_Read_Basic_ACL_Version_Candela_File_Version_Minor.ConditionCheckRead
            OpServerCallDcm_MainFunction_ReadData_DataServices_Access_Control_List_Version_Read_Basic_ACL_Version_Candela_File_Version_Major: operation=DataServices_Access_Control_List_Version_Read_Basic_ACL_Version_Candela_File_Version_Major.ReadData
            OpServerCallDcm_MainFunction_ConditionCheckRead_DataServices_Access_Control_List_Version_Read_Basic_ACL_Version_Candela_a27c07f0: operation=DataServices_Access_Control_List_Version_Read_Basic_ACL_Version_Candela_File_Version_Major.ConditionCheckRead
            OpServerCallDcm_MainFunction_ReadData_DataServices_SecOC_Local_TickCount_Read_TickCount: operation=DataServices_SecOC_Local_TickCount_Read_TickCount.ReadData
            OpServerCallDcm_MainFunction_ConditionCheckRead_DataServices_SecOC_Local_TickCount_Read_TickCount: operation=DataServices_SecOC_Local_TickCount_Read_TickCount.ConditionCheckRead
            OpServerCallDcm_MainFunction_ReadData_DataServices_HardwareVersion_Read_HW_year: operation=DataServices_HardwareVersion_Read_HW_year.ReadData
            OpServerCallDcm_MainFunction_ConditionCheckRead_DataServices_HardwareVersion_Read_HW_year: operation=DataServices_HardwareVersion_Read_HW_year.ConditionCheckRead
            OpServerCallDcm_MainFunction_ReadData_DataServices_HardwareVersion_Read_HW_week: operation=DataServices_HardwareVersion_Read_HW_week.ReadData
            OpServerCallDcm_MainFunction_ConditionCheckRead_DataServices_HardwareVersion_Read_HW_week: operation=DataServices_HardwareVersion_Read_HW_week.ConditionCheckRead
            OpServerCallDcm_MainFunction_ReadData_DataServices_HardwareVersion_Read_HW_patch_level: operation=DataServices_HardwareVersion_Read_HW_patch_level.ReadData
            OpServerCallDcm_MainFunction_ConditionCheckRead_DataServices_HardwareVersion_Read_HW_patch_level: operation=DataServices_HardwareVersion_Read_HW_patch_level.ConditionCheckRead
            OpServerCallDcm_MainFunction_Indication_ServiceRequestManufacturerNotification_DcmDslServiceRequestManufacturerNotifica_a9cb2397: operation=ServiceRequestManufacturerNotification_DcmDslServiceRequestManufacturerNotification_RightsM.Indication
            OpServerCallDcm_MainFunction_Confirmation_ServiceRequestManufacturerNotification_DcmDslServiceRequestManufacturerNotifi_201e227a: operation=ServiceRequestManufacturerNotification_DcmDslServiceRequestManufacturerNotification_RightsM.Confirmation
            OpServerCallDcm_MainFunction_Indication_ServiceRequestManufacturerNotification_DcmDslServiceRequestManufacturerNotifica_86ad7b66: operation=ServiceRequestManufacturerNotification_DcmDslServiceRequestManufacturerNotification_Coding.Indication
            OpServerCallDcm_MainFunction_Confirmation_ServiceRequestManufacturerNotification_DcmDslServiceRequestManufacturerNotifi_808776ff: operation=ServiceRequestManufacturerNotification_DcmDslServiceRequestManufacturerNotification_Coding.Confirmation
            OpServerCallDcm_MainFunction_Indication_ServiceRequestManufacturerNotification_DcmDslServiceRequestManufacturerNotifica_f61f0937: operation=ServiceRequestManufacturerNotification_DcmDslServiceRequestManufacturerNotification_ResetPreconditionCheck.Indication
            OpServerCallDcm_MainFunction_Confirmation_ServiceRequestManufacturerNotification_DcmDslServiceRequestManufacturerNotifi_d206db11: operation=ServiceRequestManufacturerNotification_DcmDslServiceRequestManufacturerNotification_ResetPreconditionCheck.Confirmation
            OpServerCallDcm_MainFunction_ReadData_DataServices_ECU_Location_Read_Side_Allocation: operation=DataServices_ECU_Location_Read_Side_Allocation.ReadData
            OpServerCallDcm_MainFunction_WriteData_DataServices_ECU_Location_Read_Side_Allocation: operation=DataServices_ECU_Location_Read_Side_Allocation.WriteData
            OpServerCallDcm_MainFunction_ReadData_DataServices_Cycle_configuration_Read_Cycles: operation=DataServices_Cycle_configuration_Read_Cycles.ReadData
            OpServerCallDcm_MainFunction_WriteData_DataServices_Cycle_configuration_Read_Cycles: operation=DataServices_Cycle_configuration_Read_Cycles.WriteData
            OpServerCallDcm_MainFunction_ReadData_DataServices_Steps_library_Read_Steps: operation=DataServices_Steps_library_Read_Steps.ReadData
            OpServerCallDcm_MainFunction_WriteData_DataServices_Steps_library_Read_Steps: operation=DataServices_Steps_library_Read_Steps.WriteData
            OpServerCallDcm_MainFunction_WriteData_DataServices_Seatbelt_Serial_Number_Read_Unique_Seatbelt_Serialnumber: operation=DataServices_Seatbelt_Serial_Number_Read_Unique_Seatbelt_Serialnumber.WriteData
            OpServerCallDcm_MainFunction_Start_RoutineServices_Routine_Status_of_Post_Production_Flag_Start: operation=RoutineServices_Routine_Status_of_Post_Production_Flag_Start.Start
            OpServerCallDcm_MainFunction_Stop_RoutineServices_Routine_Status_of_Post_Production_Flag_Start: operation=RoutineServices_Routine_Status_of_Post_Production_Flag_Start.Stop
            OpServerCallDcm_MainFunction_RequestResults_RoutineServices_Routine_Status_of_Post_Production_Flag_Start: operation=RoutineServices_Routine_Status_of_Post_Production_Flag_Start.RequestResults
            OpServerCallDcm_MainFunction_Start_RoutineServices_Routine_Trigger_Presafe_Display_Request_Start: operation=RoutineServices_Routine_Trigger_Presafe_Display_Request_Start.Start
            OpServerCallDcm_MainFunction_Stop_RoutineServices_Routine_Trigger_Presafe_Display_Request_Start: operation=RoutineServices_Routine_Trigger_Presafe_Display_Request_Start.Stop
            OpServerCallDcm_MainFunction_RequestResults_RoutineServices_Routine_Trigger_Presafe_Display_Request_Start: operation=RoutineServices_Routine_Trigger_Presafe_Display_Request_Start.RequestResults
            OpServerCallDcm_MainFunction_Start_RoutineServices_Routine_Trigger_BSR_Start: operation=RoutineServices_Routine_Trigger_BSR_Start.Start
            OpServerCallDcm_MainFunction_Stop_RoutineServices_Routine_Trigger_BSR_Start: operation=RoutineServices_Routine_Trigger_BSR_Start.Stop
            OpServerCallDcm_MainFunction_RequestResults_RoutineServices_Routine_Trigger_BSR_Start: operation=RoutineServices_Routine_Trigger_BSR_Start.RequestResults
            OpServerCallDcm_MainFunction_Start_RoutineServices_Routine_Trigger_Tensioning_Cycle_Start: operation=RoutineServices_Routine_Trigger_Tensioning_Cycle_Start.Start
            OpServerCallDcm_MainFunction_Stop_RoutineServices_Routine_Trigger_Tensioning_Cycle_Start: operation=RoutineServices_Routine_Trigger_Tensioning_Cycle_Start.Stop
            OpServerCallDcm_MainFunction_RequestResults_RoutineServices_Routine_Trigger_Tensioning_Cycle_Start: operation=RoutineServices_Routine_Trigger_Tensioning_Cycle_Start.RequestResults
            OpServerCallDcm_MainFunction_ReadData_DataServices_Obsolescence_Data_Read_Obsolescence_Data_haptic_Warning_Threshold_Ye_c8db6347: operation=DataServices_Obsolescence_Data_Read_Obsolescence_Data_haptic_Warning_Threshold_Yellow_to_Red.ReadData
            OpServerCallDcm_MainFunction_ConditionCheckRead_DataServices_Obsolescence_Data_Read_Obsolescence_Data_haptic_Warning_Th_884e51b6: operation=DataServices_Obsolescence_Data_Read_Obsolescence_Data_haptic_Warning_Threshold_Yellow_to_Red.ConditionCheckRead
            OpServerCallDcm_MainFunction_ReadData_DataServices_Obsolescence_Data_Read_Obsolescence_Data_PRE_SAFE_Lvl_4_5_Threshold_02a661ce: operation=DataServices_Obsolescence_Data_Read_Obsolescence_Data_PRE_SAFE_Lvl_4_5_Threshold_Green_to_Yellow.ReadData
            OpServerCallDcm_MainFunction_ConditionCheckRead_DataServices_Obsolescence_Data_Read_Obsolescence_Data_PRE_SAFE_Lvl_4_5_61791e3d: operation=DataServices_Obsolescence_Data_Read_Obsolescence_Data_PRE_SAFE_Lvl_4_5_Threshold_Green_to_Yellow.ConditionCheckRead
            OpServerCallDcm_MainFunction_ReadData_DataServices_Obsolescence_Data_Read_Obsolescence_Data_BSR_Threshold_Yellow_to_Red: operation=DataServices_Obsolescence_Data_Read_Obsolescence_Data_BSR_Threshold_Yellow_to_Red.ReadData
            OpServerCallDcm_MainFunction_ConditionCheckRead_DataServices_Obsolescence_Data_Read_Obsolescence_Data_BSR_Threshold_Yel_2b30f511: operation=DataServices_Obsolescence_Data_Read_Obsolescence_Data_BSR_Threshold_Yellow_to_Red.ConditionCheckRead
            OpServerCallDcm_MainFunction_ReadData_DataServices_Obsolescence_Data_Read_Obsolescence_Data_haptic_Warning_Threshold_Gr_145d1010: operation=DataServices_Obsolescence_Data_Read_Obsolescence_Data_haptic_Warning_Threshold_Green_to_Yellow.ReadData
            OpServerCallDcm_MainFunction_ConditionCheckRead_DataServices_Obsolescence_Data_Read_Obsolescence_Data_haptic_Warning_Th_d12dd1f9: operation=DataServices_Obsolescence_Data_Read_Obsolescence_Data_haptic_Warning_Threshold_Green_to_Yellow.ConditionCheckRead
            OpServerCallDcm_MainFunction_ReadData_DataServices_Obsolescence_Data_Read_Obsolescence_Data_BSR_Current_Value: operation=DataServices_Obsolescence_Data_Read_Obsolescence_Data_BSR_Current_Value.ReadData
            OpServerCallDcm_MainFunction_ConditionCheckRead_DataServices_Obsolescence_Data_Read_Obsolescence_Data_BSR_Current_Value: operation=DataServices_Obsolescence_Data_Read_Obsolescence_Data_BSR_Current_Value.ConditionCheckRead
            OpServerCallDcm_MainFunction_ReadData_DataServices_Obsolescence_Data_Read_Obsolescence_Data_PRE_CRASH_Threshold_Yellow_to_Red: operation=DataServices_Obsolescence_Data_Read_Obsolescence_Data_PRE_CRASH_Threshold_Yellow_to_Red.ReadData
            OpServerCallDcm_MainFunction_ConditionCheckRead_DataServices_Obsolescence_Data_Read_Obsolescence_Data_PRE_CRASH_Thresho_42ef91d6: operation=DataServices_Obsolescence_Data_Read_Obsolescence_Data_PRE_CRASH_Threshold_Yellow_to_Red.ConditionCheckRead
            OpServerCallDcm_MainFunction_ReadData_DataServices_Obsolescence_Data_Read_Obsolescence_Data_PRE_SAFE_Lvl_4_5_Threshold_a499344c: operation=DataServices_Obsolescence_Data_Read_Obsolescence_Data_PRE_SAFE_Lvl_4_5_Threshold_Yellow_to_Red.ReadData
            OpServerCallDcm_MainFunction_ConditionCheckRead_DataServices_Obsolescence_Data_Read_Obsolescence_Data_PRE_SAFE_Lvl_4_5_61e9f5a5: operation=DataServices_Obsolescence_Data_Read_Obsolescence_Data_PRE_SAFE_Lvl_4_5_Threshold_Yellow_to_Red.ConditionCheckRead
            OpServerCallDcm_MainFunction_ReadData_DataServices_Obsolescence_Data_Read_Obsolescence_Data_PRE_CRASH_Threshold_Green_to_Yellow: operation=DataServices_Obsolescence_Data_Read_Obsolescence_Data_PRE_CRASH_Threshold_Green_to_Yellow.ReadData
            OpServerCallDcm_MainFunction_ConditionCheckRead_DataServices_Obsolescence_Data_Read_Obsolescence_Data_PRE_CRASH_Thresho_2fb4b24f: operation=DataServices_Obsolescence_Data_Read_Obsolescence_Data_PRE_CRASH_Threshold_Green_to_Yellow.ConditionCheckRead
            OpServerCallDcm_MainFunction_ReadData_DataServices_Obsolescence_Data_Read_Obsolescence_Data_PRE_SAFE_Lvl_4_5_Current_Value: operation=DataServices_Obsolescence_Data_Read_Obsolescence_Data_PRE_SAFE_Lvl_4_5_Current_Value.ReadData
            OpServerCallDcm_MainFunction_ConditionCheckRead_DataServices_Obsolescence_Data_Read_Obsolescence_Data_PRE_SAFE_Lvl_4_5_20cee6e9: operation=DataServices_Obsolescence_Data_Read_Obsolescence_Data_PRE_SAFE_Lvl_4_5_Current_Value.ConditionCheckRead
            OpServerCallDcm_MainFunction_ReadData_DataServices_Obsolescence_Data_Read_Obsolescence_Data_haptic_Warning_Current_Value: operation=DataServices_Obsolescence_Data_Read_Obsolescence_Data_haptic_Warning_Current_Value.ReadData
            OpServerCallDcm_MainFunction_ConditionCheckRead_DataServices_Obsolescence_Data_Read_Obsolescence_Data_haptic_Warning_Cu_be3147da: operation=DataServices_Obsolescence_Data_Read_Obsolescence_Data_haptic_Warning_Current_Value.ConditionCheckRead
            OpServerCallDcm_MainFunction_ReadData_DataServices_Obsolescence_Data_Read_Obsolescence_Data_BSR_Threshold_Green_to_Yellow: operation=DataServices_Obsolescence_Data_Read_Obsolescence_Data_BSR_Threshold_Green_to_Yellow.ReadData
            OpServerCallDcm_MainFunction_ConditionCheckRead_DataServices_Obsolescence_Data_Read_Obsolescence_Data_BSR_Threshold_Gre_e1d03f58: operation=DataServices_Obsolescence_Data_Read_Obsolescence_Data_BSR_Threshold_Green_to_Yellow.ConditionCheckRead
            OpServerCallDcm_MainFunction_ReadData_DataServices_Obsolescence_Data_Read_Obsolescence_Data_PRE_CRASH_Current_Value: operation=DataServices_Obsolescence_Data_Read_Obsolescence_Data_PRE_CRASH_Current_Value.ReadData
            OpServerCallDcm_MainFunction_ConditionCheckRead_DataServices_Obsolescence_Data_Read_Obsolescence_Data_PRE_CRASH_Current_Value: operation=DataServices_Obsolescence_Data_Read_Obsolescence_Data_PRE_CRASH_Current_Value.ConditionCheckRead
            OpServerCallDcm_MainFunction_ReadData_DataServices_Availability_Data_Read_Availability_Data_PRE_SAFE_haptic_warning: operation=DataServices_Availability_Data_Read_Availability_Data_PRE_SAFE_haptic_warning.ReadData
            OpServerCallDcm_MainFunction_ConditionCheckRead_DataServices_Availability_Data_Read_Availability_Data_PRE_SAFE_haptic_warning: operation=DataServices_Availability_Data_Read_Availability_Data_PRE_SAFE_haptic_warning.ConditionCheckRead
            OpServerCallDcm_MainFunction_ReadData_DataServices_Standard_Application_SW_Package_Information_Read_AUTOSAR_Platform: operation=DataServices_Standard_Application_SW_Package_Information_Read_AUTOSAR_Platform.ReadData
            OpServerCallDcm_MainFunction_ConditionCheckRead_DataServices_Standard_Application_SW_Package_Information_Read_AUTOSAR_Platform: operation=DataServices_Standard_Application_SW_Package_Information_Read_AUTOSAR_Platform.ConditionCheckRead
            OpServerCallDcm_MainFunction_ReadData_DataServices_CAN_output_Read_PS_Curve_XX_Stat_ST3: operation=DataServices_CAN_output_Read_PS_Curve_XX_Stat_ST3.ReadData
            OpServerCallDcm_MainFunction_ConditionCheckRead_DataServices_CAN_output_Read_PS_Curve_XX_Stat_ST3: operation=DataServices_CAN_output_Read_PS_Curve_XX_Stat_ST3.ConditionCheckRead
            OpServerCallDcm_MainFunction_ReadData_DataServices_CAN_output_Read_RBTMxx_Actv_Lvl_ST35: operation=DataServices_CAN_output_Read_RBTMxx_Actv_Lvl_ST35.ReadData
            OpServerCallDcm_MainFunction_ConditionCheckRead_DataServices_CAN_output_Read_RBTMxx_Actv_Lvl_ST35: operation=DataServices_CAN_output_Read_RBTMxx_Actv_Lvl_ST35.ConditionCheckRead
            OpServerCallDcm_MainFunction_ReadData_DataServices_CAN_output_Read_RBTMxx_SP_ActvClient_ST35: operation=DataServices_CAN_output_Read_RBTMxx_SP_ActvClient_ST35.ReadData
            OpServerCallDcm_MainFunction_ConditionCheckRead_DataServices_CAN_output_Read_RBTMxx_SP_ActvClient_ST35: operation=DataServices_CAN_output_Read_RBTMxx_SP_ActvClient_ST35.ConditionCheckRead
            OpServerCallDcm_MainFunction_ReadData_DataServices_CAN_output_Read_RBTMxx_SP_FctPrecond_Stat_ST35: operation=DataServices_CAN_output_Read_RBTMxx_SP_FctPrecond_Stat_ST35.ReadData
            OpServerCallDcm_MainFunction_ConditionCheckRead_DataServices_CAN_output_Read_RBTMxx_SP_FctPrecond_Stat_ST35: operation=DataServices_CAN_output_Read_RBTMxx_SP_FctPrecond_Stat_ST35.ConditionCheckRead
            OpServerCallDcm_MainFunction_ReadData_DataServices_Trust_Model_Root_Replacement_Key_Read_Root_Replacement_Key: operation=DataServices_Trust_Model_Root_Replacement_Key_Read_Root_Replacement_Key.ReadData
            OpServerCallDcm_MainFunction_ConditionCheckRead_DataServices_Trust_Model_Root_Replacement_Key_Read_Root_Replacement_Key: operation=DataServices_Trust_Model_Root_Replacement_Key_Read_Root_Replacement_Key.ConditionCheckRead
            OpServerCallDcm_MainFunction_ReadData_DataServices_Last_Warm_Reset_Parameters_Read_Reset_Cause_Counter: operation=DataServices_Last_Warm_Reset_Parameters_Read_Reset_Cause_Counter.ReadData
            OpServerCallDcm_MainFunction_ConditionCheckRead_DataServices_Last_Warm_Reset_Parameters_Read_Reset_Cause_Counter: operation=DataServices_Last_Warm_Reset_Parameters_Read_Reset_Cause_Counter.ConditionCheckRead
            OpServerCallDcm_MainFunction_ReadData_DataServices_Last_Warm_Reset_Parameters_Read_Last_Detected_Warm_Reset_Cause: operation=DataServices_Last_Warm_Reset_Parameters_Read_Last_Detected_Warm_Reset_Cause.ReadData
            OpServerCallDcm_MainFunction_ConditionCheckRead_DataServices_Last_Warm_Reset_Parameters_Read_Last_Detected_Warm_Reset_Cause: operation=DataServices_Last_Warm_Reset_Parameters_Read_Last_Detected_Warm_Reset_Cause.ConditionCheckRead
            OpServerCallDcm_MainFunction_Start_RoutineServices_Routine_Cycle_Execution_Start: operation=RoutineServices_Routine_Cycle_Execution_Start.Start
            OpServerCallDcm_MainFunction_Stop_RoutineServices_Routine_Cycle_Execution_Start: operation=RoutineServices_Routine_Cycle_Execution_Start.Stop
            OpServerCallDcm_MainFunction_RequestResults_RoutineServices_Routine_Cycle_Execution_Start: operation=RoutineServices_Routine_Cycle_Execution_Start.RequestResults
            OpServerCallDcm_MainFunction_ReadData_DataServices_Measurement_Frames_Configuration_Read_CombinedSignal: operation=DataServices_Measurement_Frames_Configuration_Read_CombinedSignal.ReadData
            OpServerCallDcm_MainFunction_ConditionCheckRead_DataServices_Measurement_Frames_Configuration_Read_CombinedSignal: operation=DataServices_Measurement_Frames_Configuration_Read_CombinedSignal.ConditionCheckRead
            OpServerCallDcm_MainFunction_WriteData_DataServices_Measurement_Frames_Configuration_Read_CombinedSignal: operation=DataServices_Measurement_Frames_Configuration_Read_CombinedSignal.WriteData
            OpServerCallDcm_MainFunction_ReadData_DataServices_Measurement_Frame_Block_12_Config_Read_CombinedSignal: operation=DataServices_Measurement_Frame_Block_12_Config_Read_CombinedSignal.ReadData
            OpServerCallDcm_MainFunction_ConditionCheckRead_DataServices_Measurement_Frame_Block_12_Config_Read_CombinedSignal: operation=DataServices_Measurement_Frame_Block_12_Config_Read_CombinedSignal.ConditionCheckRead
            OpServerCallDcm_MainFunction_WriteData_DataServices_Measurement_Frame_Block_12_Config_Read_CombinedSignal: operation=DataServices_Measurement_Frame_Block_12_Config_Read_CombinedSignal.WriteData
            OpServerCallDcm_MainFunction_ReadData_DataServices_HB_Calibration_Read_CombinedSignal: operation=DataServices_HB_Calibration_Read_CombinedSignal.ReadData
            OpServerCallDcm_MainFunction_ConditionCheckRead_DataServices_HB_Calibration_Read_CombinedSignal: operation=DataServices_HB_Calibration_Read_CombinedSignal.ConditionCheckRead
            OpServerCallDcm_MainFunction_WriteData_DataServices_HB_Calibration_Read_CombinedSignal: operation=DataServices_HB_Calibration_Read_CombinedSignal.WriteData
            OpServerCallDcm_MainFunction_ReadData_DataServices_AEC_Status_Read_AEC_Status: operation=DataServices_AEC_Status_Read_AEC_Status.ReadData
            OpServerCallDcm_MainFunction_ReadDataLength_DataServices_AEC_Status_Read_AEC_Status: operation=DataServices_AEC_Status_Read_AEC_Status.ReadDataLength
            OpServerCallDcm_MainFunction_ConditionCheckRead_DataServices_AEC_Status_Read_AEC_Status: operation=DataServices_AEC_Status_Read_AEC_Status.ConditionCheckRead
            OpServerCallDcm_MainFunction_ReadData_DataServices_Reset_Cause_Management_Read_Reset_Cause: operation=DataServices_Reset_Cause_Management_Read_Reset_Cause.ReadData
            OpServerCallDcm_MainFunction_ConditionCheckRead_DataServices_Reset_Cause_Management_Read_Reset_Cause: operation=DataServices_Reset_Cause_Management_Read_Reset_Cause.ConditionCheckRead
            OpServerCallDcm_MainFunction_Start_RoutineServices_Routine_Clear_Resource_Consumption_Data_Start: operation=RoutineServices_Routine_Clear_Resource_Consumption_Data_Start.Start
            OpServerCallDcm_MainFunction_ReadData_DataServices_Task_Response_Time_Read_Task_histograms: operation=DataServices_Task_Response_Time_Read_Task_histograms.ReadData
            OpServerCallDcm_MainFunction_ReadDataLength_DataServices_Task_Response_Time_Read_Task_histograms: operation=DataServices_Task_Response_Time_Read_Task_histograms.ReadDataLength
            OpServerCallDcm_MainFunction_ConditionCheckRead_DataServices_Task_Response_Time_Read_Task_histograms: operation=DataServices_Task_Response_Time_Read_Task_histograms.ConditionCheckRead
            OpServerCallDcm_MainFunction_ReadData_DataServices_Stack_Load_Read_Maximum: operation=DataServices_Stack_Load_Read_Maximum.ReadData
            OpServerCallDcm_MainFunction_ReadDataLength_DataServices_Stack_Load_Read_Maximum: operation=DataServices_Stack_Load_Read_Maximum.ReadDataLength
            OpServerCallDcm_MainFunction_ConditionCheckRead_DataServices_Stack_Load_Read_Maximum: operation=DataServices_Stack_Load_Read_Maximum.ConditionCheckRead
            OpServerCallDcm_MainFunction_ReadData_DataServices_CPU_Load_Read_CPU_load_histograms: operation=DataServices_CPU_Load_Read_CPU_load_histograms.ReadData
            OpServerCallDcm_MainFunction_ReadDataLength_DataServices_CPU_Load_Read_CPU_load_histograms: operation=DataServices_CPU_Load_Read_CPU_load_histograms.ReadDataLength
            OpServerCallDcm_MainFunction_ConditionCheckRead_DataServices_CPU_Load_Read_CPU_load_histograms: operation=DataServices_CPU_Load_Read_CPU_load_histograms.ConditionCheckRead
            OpServerCallDcm_MainFunction_ReadData_DataServices_Vehicle_Equipment_Read_Equipment_6: operation=DataServices_Vehicle_Equipment_Read_Equipment_6.ReadData
            OpServerCallDcm_MainFunction_ConditionCheckRead_DataServices_Vehicle_Equipment_Read_Equipment_6: operation=DataServices_Vehicle_Equipment_Read_Equipment_6.ConditionCheckRead
            OpServerCallDcm_MainFunction_WriteData_DataServices_Vehicle_Equipment_Read_Equipment_6: operation=DataServices_Vehicle_Equipment_Read_Equipment_6.WriteData
            OpServerCallDcm_MainFunction_ReadData_DataServices_Vehicle_Equipment_Read_Equipment_5: operation=DataServices_Vehicle_Equipment_Read_Equipment_5.ReadData
            OpServerCallDcm_MainFunction_ConditionCheckRead_DataServices_Vehicle_Equipment_Read_Equipment_5: operation=DataServices_Vehicle_Equipment_Read_Equipment_5.ConditionCheckRead
            OpServerCallDcm_MainFunction_WriteData_DataServices_Vehicle_Equipment_Read_Equipment_5: operation=DataServices_Vehicle_Equipment_Read_Equipment_5.WriteData
            OpServerCallDcm_MainFunction_ReadData_DataServices_Vehicle_Equipment_Read_Equipment_4: operation=DataServices_Vehicle_Equipment_Read_Equipment_4.ReadData
            OpServerCallDcm_MainFunction_ConditionCheckRead_DataServices_Vehicle_Equipment_Read_Equipment_4: operation=DataServices_Vehicle_Equipment_Read_Equipment_4.ConditionCheckRead
            OpServerCallDcm_MainFunction_WriteData_DataServices_Vehicle_Equipment_Read_Equipment_4: operation=DataServices_Vehicle_Equipment_Read_Equipment_4.WriteData
            OpServerCallDcm_MainFunction_ReadData_DataServices_Tensioning_Cycle_BSR_Read_CombinedSignal: operation=DataServices_Tensioning_Cycle_BSR_Read_CombinedSignal.ReadData
            OpServerCallDcm_MainFunction_ConditionCheckRead_DataServices_Tensioning_Cycle_BSR_Read_CombinedSignal: operation=DataServices_Tensioning_Cycle_BSR_Read_CombinedSignal.ConditionCheckRead
            OpServerCallDcm_MainFunction_WriteData_DataServices_Tensioning_Cycle_BSR_Read_CombinedSignal: operation=DataServices_Tensioning_Cycle_BSR_Read_CombinedSignal.WriteData
            OpServerCallDcm_MainFunction_ReadData_DataServices_Release_Cycles_BSR_and_PreSafe_Read_CombinedSignal: operation=DataServices_Release_Cycles_BSR_and_PreSafe_Read_CombinedSignal.ReadData
            OpServerCallDcm_MainFunction_ConditionCheckRead_DataServices_Release_Cycles_BSR_and_PreSafe_Read_CombinedSignal: operation=DataServices_Release_Cycles_BSR_and_PreSafe_Read_CombinedSignal.ConditionCheckRead
            OpServerCallDcm_MainFunction_WriteData_DataServices_Release_Cycles_BSR_and_PreSafe_Read_CombinedSignal: operation=DataServices_Release_Cycles_BSR_and_PreSafe_Read_CombinedSignal.WriteData
            OpServerCallDcm_MainFunction_ReadData_DataServices_PreSafe_Cycles_Level_1_8_Read_CombinedSignal: operation=DataServices_PreSafe_Cycles_Level_1_8_Read_CombinedSignal.ReadData
            OpServerCallDcm_MainFunction_ConditionCheckRead_DataServices_PreSafe_Cycles_Level_1_8_Read_CombinedSignal: operation=DataServices_PreSafe_Cycles_Level_1_8_Read_CombinedSignal.ConditionCheckRead
            OpServerCallDcm_MainFunction_WriteData_DataServices_PreSafe_Cycles_Level_1_8_Read_CombinedSignal: operation=DataServices_PreSafe_Cycles_Level_1_8_Read_CombinedSignal.WriteData
            OpServerCallDcm_MainFunction_ReadData_DataServices_Global_Time_Sync_Measured_Values_Read_GTSM: operation=DataServices_Global_Time_Sync_Measured_Values_Read_GTSM.ReadData
            OpServerCallDcm_MainFunction_ReadDataLength_DataServices_Global_Time_Sync_Measured_Values_Read_GTSM: operation=DataServices_Global_Time_Sync_Measured_Values_Read_GTSM.ReadDataLength
            OpServerCallDcm_MainFunction_ConditionCheckRead_DataServices_Global_Time_Sync_Measured_Values_Read_GTSM: operation=DataServices_Global_Time_Sync_Measured_Values_Read_GTSM.ConditionCheckRead
            OpServerCallDcm_MainFunction_ReadData_DataServices_Memory_Usage_Cycles_Read_Memory_Usage_Cycles: operation=DataServices_Memory_Usage_Cycles_Read_Memory_Usage_Cycles.ReadData
            OpServerCallDcm_MainFunction_ReadDataLength_DataServices_Memory_Usage_Cycles_Read_Memory_Usage_Cycles: operation=DataServices_Memory_Usage_Cycles_Read_Memory_Usage_Cycles.ReadDataLength
            OpServerCallDcm_MainFunction_ConditionCheckRead_DataServices_Memory_Usage_Cycles_Read_Memory_Usage_Cycles: operation=DataServices_Memory_Usage_Cycles_Read_Memory_Usage_Cycles.ConditionCheckRead
            OpServerCallDcm_MainFunction_ReadData_DataServices_CAN_input_Read_Neues_Bitfeld_8: operation=DataServices_CAN_input_Read_Neues_Bitfeld_8.ReadData
            OpServerCallDcm_MainFunction_ConditionCheckRead_DataServices_CAN_input_Read_Neues_Bitfeld_8: operation=DataServices_CAN_input_Read_Neues_Bitfeld_8.ConditionCheckRead
            OpServerCallDcm_MainFunction_ReadData_DataServices_CAN_input_Read_Neues_Bitfeld_7: operation=DataServices_CAN_input_Read_Neues_Bitfeld_7.ReadData
            OpServerCallDcm_MainFunction_ConditionCheckRead_DataServices_CAN_input_Read_Neues_Bitfeld_7: operation=DataServices_CAN_input_Read_Neues_Bitfeld_7.ConditionCheckRead
            OpServerCallDcm_MainFunction_ReadData_DataServices_HSM_Identification_Read_HSM_MB_Version_HW_patch_level: operation=DataServices_HSM_Identification_Read_HSM_MB_Version_HW_patch_level.ReadData
            OpServerCallDcm_MainFunction_ConditionCheckRead_DataServices_HSM_Identification_Read_HSM_MB_Version_HW_patch_level: operation=DataServices_HSM_Identification_Read_HSM_MB_Version_HW_patch_level.ConditionCheckRead
            OpServerCallDcm_MainFunction_WriteData_DataServices_HSM_Identification_Read_HSM_MB_Version_HW_patch_level: operation=DataServices_HSM_Identification_Read_HSM_MB_Version_HW_patch_level.WriteData
            OpServerCallDcm_MainFunction_ReadData_DataServices_HSM_Identification_Read_HSM_MB_Supplier_Version_HW_week: operation=DataServices_HSM_Identification_Read_HSM_MB_Supplier_Version_HW_week.ReadData
            OpServerCallDcm_MainFunction_ConditionCheckRead_DataServices_HSM_Identification_Read_HSM_MB_Supplier_Version_HW_week: operation=DataServices_HSM_Identification_Read_HSM_MB_Supplier_Version_HW_week.ConditionCheckRead
            OpServerCallDcm_MainFunction_WriteData_DataServices_HSM_Identification_Read_HSM_MB_Supplier_Version_HW_week: operation=DataServices_HSM_Identification_Read_HSM_MB_Supplier_Version_HW_week.WriteData
            OpServerCallDcm_MainFunction_ReadData_DataServices_HSM_Identification_Read_HSM_MB_Supplier_Version_HW_patch_level: operation=DataServices_HSM_Identification_Read_HSM_MB_Supplier_Version_HW_patch_level.ReadData
            OpServerCallDcm_MainFunction_ConditionCheckRead_DataServices_HSM_Identification_Read_HSM_MB_Supplier_Version_HW_patch_level: operation=DataServices_HSM_Identification_Read_HSM_MB_Supplier_Version_HW_patch_level.ConditionCheckRead
            OpServerCallDcm_MainFunction_WriteData_DataServices_HSM_Identification_Read_HSM_MB_Supplier_Version_HW_patch_level: operation=DataServices_HSM_Identification_Read_HSM_MB_Supplier_Version_HW_patch_level.WriteData
            OpServerCallDcm_MainFunction_ReadData_DataServices_HSM_Identification_Read_HSM_MB_Version_HW_year: operation=DataServices_HSM_Identification_Read_HSM_MB_Version_HW_year.ReadData
            OpServerCallDcm_MainFunction_ConditionCheckRead_DataServices_HSM_Identification_Read_HSM_MB_Version_HW_year: operation=DataServices_HSM_Identification_Read_HSM_MB_Version_HW_year.ConditionCheckRead
            OpServerCallDcm_MainFunction_WriteData_DataServices_HSM_Identification_Read_HSM_MB_Version_HW_year: operation=DataServices_HSM_Identification_Read_HSM_MB_Version_HW_year.WriteData
            OpServerCallDcm_MainFunction_ReadData_DataServices_HSM_Identification_Read_HSM_MB_Partnumber: operation=DataServices_HSM_Identification_Read_HSM_MB_Partnumber.ReadData
            OpServerCallDcm_MainFunction_ConditionCheckRead_DataServices_HSM_Identification_Read_HSM_MB_Partnumber: operation=DataServices_HSM_Identification_Read_HSM_MB_Partnumber.ConditionCheckRead
            OpServerCallDcm_MainFunction_WriteData_DataServices_HSM_Identification_Read_HSM_MB_Partnumber: operation=DataServices_HSM_Identification_Read_HSM_MB_Partnumber.WriteData
            OpServerCallDcm_MainFunction_ReadData_DataServices_HSM_Identification_Read_HSM_MB_Supplier_Version_HW_year: operation=DataServices_HSM_Identification_Read_HSM_MB_Supplier_Version_HW_year.ReadData
            OpServerCallDcm_MainFunction_ConditionCheckRead_DataServices_HSM_Identification_Read_HSM_MB_Supplier_Version_HW_year: operation=DataServices_HSM_Identification_Read_HSM_MB_Supplier_Version_HW_year.ConditionCheckRead
            OpServerCallDcm_MainFunction_WriteData_DataServices_HSM_Identification_Read_HSM_MB_Supplier_Version_HW_year: operation=DataServices_HSM_Identification_Read_HSM_MB_Supplier_Version_HW_year.WriteData
            OpServerCallDcm_MainFunction_ReadData_DataServices_HSM_Identification_Read_HSM_MB_Version_HW_week: operation=DataServices_HSM_Identification_Read_HSM_MB_Version_HW_week.ReadData
            OpServerCallDcm_MainFunction_ConditionCheckRead_DataServices_HSM_Identification_Read_HSM_MB_Version_HW_week: operation=DataServices_HSM_Identification_Read_HSM_MB_Version_HW_week.ConditionCheckRead
            OpServerCallDcm_MainFunction_WriteData_DataServices_HSM_Identification_Read_HSM_MB_Version_HW_week: operation=DataServices_HSM_Identification_Read_HSM_MB_Version_HW_week.WriteData
            OpServerCallDcm_MainFunction_ReadData_DataServices_SW_Version_Read_SW_Version: operation=DataServices_SW_Version_Read_SW_Version.ReadData
            OpServerCallDcm_MainFunction_ConditionCheckRead_DataServices_SW_Version_Read_SW_Version: operation=DataServices_SW_Version_Read_SW_Version.ConditionCheckRead
            OpServerCallDcm_MainFunction_WriteData_DataServices_Hardware_Version_Information_Write_HW_year: operation=DataServices_Hardware_Version_Information_Write_HW_year.WriteData
            OpServerCallDcm_MainFunction_WriteData_DataServices_Hardware_Version_Information_Write_HW_week: operation=DataServices_Hardware_Version_Information_Write_HW_week.WriteData
            OpServerCallDcm_MainFunction_WriteData_DataServices_Hardware_Version_Information_Write_HW_patch_level: operation=DataServices_Hardware_Version_Information_Write_HW_patch_level.WriteData
            OpServerCallDcm_MainFunction_ReadData_DataServices_Standard_Application_SW_Package_Information_Read_C_P_Identification: operation=DataServices_Standard_Application_SW_Package_Information_Read_C_P_Identification.ReadData
            OpServerCallDcm_MainFunction_ConditionCheckRead_DataServices_Standard_Application_SW_Package_Information_Read_C_P_Identification: operation=DataServices_Standard_Application_SW_Package_Information_Read_C_P_Identification.ConditionCheckRead
            OpServerCallDcm_MainFunction_ReadData_DataServices_Calibration_Identifications_CAL_ID_Read_Calibration_Identification: operation=DataServices_Calibration_Identifications_CAL_ID_Read_Calibration_Identification.ReadData
            OpServerCallDcm_MainFunction_ReadDataLength_DataServices_Calibration_Identifications_CAL_ID_Read_Calibration_Identification: operation=DataServices_Calibration_Identifications_CAL_ID_Read_Calibration_Identification.ReadDataLength
            OpServerCallDcm_MainFunction_ConditionCheckRead_DataServices_Calibration_Identifications_CAL_ID_Read_Calibration_Identification: operation=DataServices_Calibration_Identifications_CAL_ID_Read_Calibration_Identification.ConditionCheckRead
            OpServerCallDcm_MainFunction_WriteData_DataServices_Calibration_Identifications_CAL_ID_Write_Calibration_Identification: operation=DataServices_Calibration_Identifications_CAL_ID_Write_Calibration_Identification.WriteData
            OpServerCallDcm_MainFunction_WriteData_DataServices_Calibration_Identifications_CAL_ID_Write_Number_of_data_items: operation=DataServices_Calibration_Identifications_CAL_ID_Write_Number_of_data_items.WriteData
            OpServerCallDcm_MainFunction_ReadData_DataServices_ECU_serial_number_Read_PCBA_Programmed_Part_number: operation=DataServices_ECU_serial_number_Read_PCBA_Programmed_Part_number.ReadData
            OpServerCallDcm_MainFunction_ConditionCheckRead_DataServices_ECU_serial_number_Read_PCBA_Programmed_Part_number: operation=DataServices_ECU_serial_number_Read_PCBA_Programmed_Part_number.ConditionCheckRead
            OpServerCallDcm_MainFunction_WriteData_DataServices_ECU_serial_number_Read_PCBA_Programmed_Part_number: operation=DataServices_ECU_serial_number_Read_PCBA_Programmed_Part_number.WriteData
            OpServerCallDcm_MainFunction_ReadData_DataServices_ECU_serial_number_Read_ECU_traceability_number: operation=DataServices_ECU_serial_number_Read_ECU_traceability_number.ReadData
            OpServerCallDcm_MainFunction_ConditionCheckRead_DataServices_ECU_serial_number_Read_ECU_traceability_number: operation=DataServices_ECU_serial_number_Read_ECU_traceability_number.ConditionCheckRead
            OpServerCallDcm_MainFunction_WriteData_DataServices_ECU_serial_number_Read_ECU_traceability_number: operation=DataServices_ECU_serial_number_Read_ECU_traceability_number.WriteData
            OpServerCallDcm_MainFunction_Start_RoutineServices_Routine_Erase_All_Start: operation=RoutineServices_Routine_Erase_All_Start.Start
            OpServerCallDcm_MainFunction_Start_RoutineServices_Routine_Force_External_WDG_Start: operation=RoutineServices_Routine_Force_External_WDG_Start.Start
            OpServerCallDcm_MainFunction_ReadData_DataServices_Customer_Settings_Read_BltSlckDec_Md_Stat: operation=DataServices_Customer_Settings_Read_BltSlckDec_Md_Stat.ReadData
            OpServerCallDcm_MainFunction_ConditionCheckRead_DataServices_Customer_Settings_Read_BltSlckDec_Md_Stat: operation=DataServices_Customer_Settings_Read_BltSlckDec_Md_Stat.ConditionCheckRead
            OpServerCallDcm_MainFunction_ReadData_DataServices_Customer_Settings_Read_PS_Curve_Stat: operation=DataServices_Customer_Settings_Read_PS_Curve_Stat.ReadData
            OpServerCallDcm_MainFunction_ConditionCheckRead_DataServices_Customer_Settings_Read_PS_Curve_Stat: operation=DataServices_Customer_Settings_Read_PS_Curve_Stat.ConditionCheckRead
            OpServerCallDcm_MainFunction_ReadData_DataServices_Trust_Model_CSR_Supplier_Signature_Read_Trust_Model_CSR_Supplier_Signature: operation=DataServices_Trust_Model_CSR_Supplier_Signature_Read_Trust_Model_CSR_Supplier_Signature.ReadData
            OpServerCallDcm_MainFunction_ReadDataLength_DataServices_Trust_Model_CSR_Supplier_Signature_Read_Trust_Model_CSR_Suppli_1a366c5c: operation=DataServices_Trust_Model_CSR_Supplier_Signature_Read_Trust_Model_CSR_Supplier_Signature.ReadDataLength
            OpServerCallDcm_MainFunction_ConditionCheckRead_DataServices_Trust_Model_CSR_Supplier_Signature_Read_Trust_Model_CSR_Su_b9890bdf: operation=DataServices_Trust_Model_CSR_Supplier_Signature_Read_Trust_Model_CSR_Supplier_Signature.ConditionCheckRead
            OpServerCallDcm_MainFunction_WriteData_DataServices_Trust_Model_CSR_Supplier_Signature_Read_Trust_Model_CSR_Supplier_Signature: operation=DataServices_Trust_Model_CSR_Supplier_Signature_Read_Trust_Model_CSR_Supplier_Signature.WriteData
            OpServerCallDcm_MainFunction_ReadData_DataServices_Velocity_PI_Regulation_Coefficient_Read_Input_Velocity_Coefficient: operation=DataServices_Velocity_PI_Regulation_Coefficient_Read_Input_Velocity_Coefficient.ReadData
            OpServerCallDcm_MainFunction_ConditionCheckRead_DataServices_Velocity_PI_Regulation_Coefficient_Read_Input_Velocity_Coefficient: operation=DataServices_Velocity_PI_Regulation_Coefficient_Read_Input_Velocity_Coefficient.ConditionCheckRead
            OpServerCallDcm_MainFunction_WriteData_DataServices_Velocity_PI_Regulation_Coefficient_Read_Input_Velocity_Coefficient: operation=DataServices_Velocity_PI_Regulation_Coefficient_Read_Input_Velocity_Coefficient.WriteData
            OpServerCallDcm_MainFunction_ReadData_DataServices_Temperature_Sensor_Calibration_Point_Read_Offset_Point: operation=DataServices_Temperature_Sensor_Calibration_Point_Read_Offset_Point.ReadData
            OpServerCallDcm_MainFunction_ConditionCheckRead_DataServices_Temperature_Sensor_Calibration_Point_Read_Offset_Point: operation=DataServices_Temperature_Sensor_Calibration_Point_Read_Offset_Point.ConditionCheckRead
            OpServerCallDcm_MainFunction_WriteData_DataServices_Temperature_Sensor_Calibration_Point_Read_Offset_Point: operation=DataServices_Temperature_Sensor_Calibration_Point_Read_Offset_Point.WriteData
        GetActiveProtocol: can-be-invoked-concurrently=true, symbol=Dcm_GetActiveProtocol
        GetSesCtrlType: can-be-invoked-concurrently=true, symbol=Dcm_GetSesCtrlType
        ResetToDefaultSession: can-be-invoked-concurrently=true, symbol=Dcm_ResetToDefaultSession
        SetActiveDiagnostic: can-be-invoked-concurrently=true, symbol=Dcm_SetActiveDiagnostic
        GetRequestKind: can-be-invoked-concurrently=true, symbol=Dcm_GetRequestKind
  swc implementation DcmImplementation: programming-language=C, behavior=DcmInternalBehavior
    resource consumption DcmResourceConsumption
      5 x memory section:
        Dcm_START_SEC_CODE: sw-addrmethod=CODE, symbol=CODE
        Dcm_START_SEC_CONST_UNSPECIFIED: alignment=UNSPECIFIED, sw-addrmethod=CONST, symbol=CONST_UNSPECIFIED
        Dcm_START_SEC_VAR_NOINIT_UNSPECIFIED: alignment=UNSPECIFIED, sw-addrmethod=VAR_NO_INIT, symbol=VAR_NOINIT_UNSPECIFIED
        Dcm_START_SEC_VAR_INIT_UNSPECIFIED: alignment=UNSPECIFIED, sw-addrmethod=VAR_INIT, symbol=VAR_INIT_UNSPECIFIED
        Dcm_START_SEC_VAR_ZERO_INIT_UNSPECIFIED: alignment=UNSPECIFIED, sw-addrmethod=VAR_CLEARED, symbol=VAR_ZERO_INIT_UNSPECIFIED
